AUTOSAR XML (schema 4-2-2)
package /STELLANTIS/EPT/ASWCs
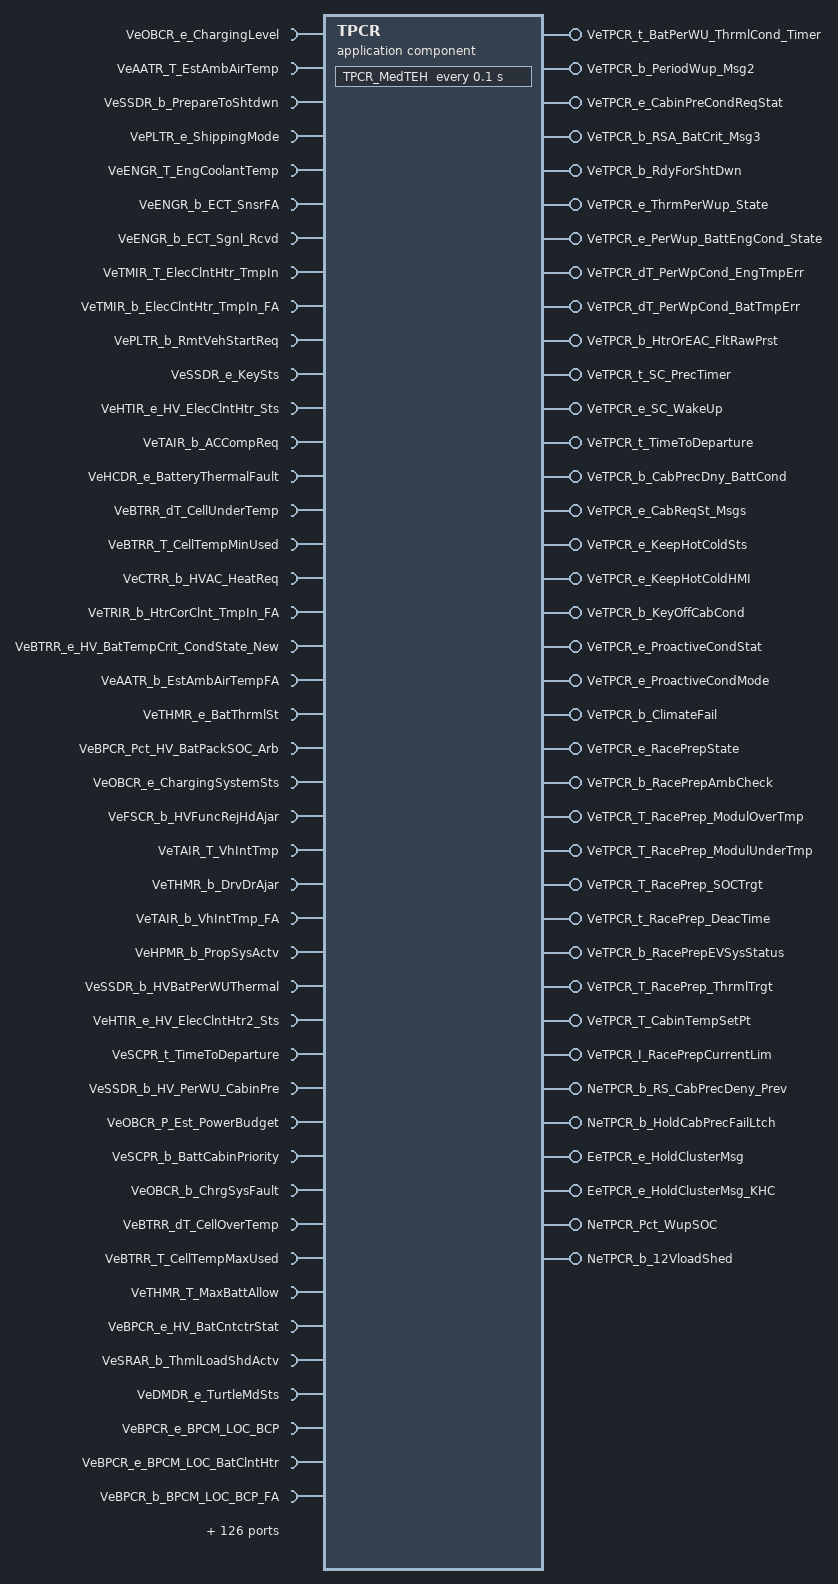
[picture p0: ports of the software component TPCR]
  application sw component type TPCR
    162 x require port:
      VeOBCR_e_ChargingLevel: variation-point={short-label=vpVeOBCR_e_ChargingLevel, sw-syscond=1}, nonqueued-receiver-com-spec{data-element=Value, init-value=CeOBCR_e_ChargingLvlDefault}, required-interface=VeOBCR_e_ChargingLevel
      VeAATR_T_EstAmbAirTemp: variation-point={short-label=vpVeAATR_T_EstAmbAirTemp, sw-syscond=1}, nonqueued-receiver-com-spec{data-element=Value, init-value=0}, required-interface=VeAATR_T_EstAmbAirTemp
      VeSSDR_b_PrepareToShtdwn: variation-point={short-label=vpVeSSDR_b_PrepareToShtdwn, sw-syscond=1}, nonqueued-receiver-com-spec{data-element=Value, init-value=0}, required-interface=VeSSDR_b_PrepareToShtdwn
      VePLTR_e_ShippingMode: variation-point={short-label=vpVePLTR_e_ShippingMode, sw-syscond=1}, nonqueued-receiver-com-spec{data-element=Value, init-value=CePLTR_e_ShipingMode_CUST_MD}, required-interface=VePLTR_e_ShippingMode
      VeENGR_T_EngCoolantTemp: variation-point={short-label=vpVeENGR_T_EngCoolantTemp, sw-syscond=1}, nonqueued-receiver-com-spec{data-element=Value, init-value=0}, required-interface=VeENGR_T_EngCoolantTemp
      VeENGR_b_ECT_SnsrFA: variation-point={short-label=vpVeENGR_b_ECT_SnsrFA, sw-syscond=1}, nonqueued-receiver-com-spec{data-element=Value, init-value=0}, required-interface=VeENGR_b_ECT_SnsrFA
      VeENGR_b_ECT_Sgnl_Rcvd: variation-point={short-label=vpVeENGR_b_ECT_Sgnl_Rcvd, sw-syscond=1}, nonqueued-receiver-com-spec{data-element=Value, init-value=0}, required-interface=VeENGR_b_ECT_Sgnl_Rcvd
      VeTMIR_T_ElecClntHtr_TmpIn: variation-point={short-label=vpVeTMIR_T_ElecClntHtr_TmpIn, sw-syscond=1}, nonqueued-receiver-com-spec{data-element=Value, init-value=0}, required-interface=VeTMIR_T_ElecClntHtr_TmpIn
      VeTMIR_b_ElecClntHtr_TmpIn_FA: variation-point={short-label=vpVeTMIR_b_ElecClntHtr_TmpIn_FA, sw-syscond=1}, nonqueued-receiver-com-spec{data-element=Value, init-value=0}, required-interface=VeTMIR_b_ElecClntHtr_TmpIn_FA
      VePLTR_b_RmtVehStartReq: variation-point={short-label=vpVePLTR_b_RmtVehStartReq, sw-syscond=1}, nonqueued-receiver-com-spec{data-element=Value, init-value=0}, required-interface=VePLTR_b_RmtVehStartReq
      VeSSDR_e_KeySts: variation-point={short-label=vpVeSSDR_e_KeySts, sw-syscond=1}, nonqueued-receiver-com-spec{data-element=Value, init-value=CeSSDR_e_KeyOff}, required-interface=VeSSDR_e_KeySts
      VeHTIR_e_HV_ElecClntHtr_Sts: variation-point={short-label=vpVeHTIR_e_HV_ElecClntHtr_Sts, sw-syscond=1}, nonqueued-receiver-com-spec{data-element=Value, init-value=CeHTIR_e_HtrSts_Off}, required-interface=VeHTIR_e_HV_ElecClntHtr_Sts
      VeTAIR_b_ACCompReq: variation-point={short-label=vpVeTAIR_b_ACCompReq, sw-syscond=1}, nonqueued-receiver-com-spec{data-element=Value, init-value=0}, required-interface=VeTAIR_b_ACCompReq
      VeHCDR_e_BatteryThermalFault: variation-point={short-label=vpVeHCDR_e_BatteryThermalFault, sw-syscond=1}, nonqueued-receiver-com-spec{data-element=Value, init-value=CeHCDR_e_BattThermalNoFault}, required-interface=VeHCDR_e_BatteryThermalFault
      VeBTRR_dT_CellUnderTemp: variation-point={short-label=vpVeBTRR_dT_CellUnderTemp, sw-syscond=1}, nonqueued-receiver-com-spec{data-element=Value, init-value=0}, required-interface=VeBTRR_dT_CellUnderTemp
      VeBTRR_T_CellTempMinUsed: variation-point={short-label=vpVeBTRR_T_CellTempMinUsed, sw-syscond=1}, nonqueued-receiver-com-spec{data-element=Value, init-value=0}, required-interface=VeBTRR_T_CellTempMinUsed
      VeCTRR_b_HVAC_HeatReq: variation-point={short-label=vpVeCTRR_b_HVAC_HeatReq, sw-syscond=1}, nonqueued-receiver-com-spec{data-element=Value, init-value=0}, required-interface=VeCTRR_b_HVAC_HeatReq
      VeTRIR_b_HtrCorClnt_TmpIn_FA: variation-point={short-label=vpVeTRIR_b_HtrCorClnt_TmpIn_FA, sw-syscond=1}, nonqueued-receiver-com-spec{data-element=Value, init-value=0}, required-interface=VeTRIR_b_HtrCorClnt_TmpIn_FA
      VeBTRR_e_HV_BatTempCrit_CondState_New: variation-point={short-label=vpVeBTRR_e_HV_BatTempCrit_CondState_New, sw-syscond=1}, nonqueued-receiver-com-spec{data-element=Value, init-value=CeBTRR_e_BatNotCrit}, required-interface=VeBTRR_e_HV_BatTempCrit_CondState_New
      VeAATR_b_EstAmbAirTempFA: variation-point={short-label=vpVeAATR_b_EstAmbAirTempFA, sw-syscond=1}, nonqueued-receiver-com-spec{data-element=Value, init-value=0}, required-interface=VeAATR_b_EstAmbAirTempFA
      VeTHMR_e_BatThrmlSt: variation-point={short-label=vpVeTHMR_e_BatThrmlSt, sw-syscond=1}, nonqueued-receiver-com-spec{data-element=Value, init-value=CeTHMR_e_NoConditioning}, required-interface=VeTHMR_e_BatThrmlSt
      VeBPCR_Pct_HV_BatPackSOC_Arb: variation-point={short-label=vpVeBPCR_Pct_HV_BatPackSOC_Arb, sw-syscond=1}, nonqueued-receiver-com-spec{data-element=Value, init-value=0}, required-interface=VeBPCR_Pct_HV_BatPackSOC_Arb
      VeOBCR_e_ChargingSystemSts: variation-point={short-label=vpVeOBCR_e_ChargingSystemSts, sw-syscond=1}, nonqueued-receiver-com-spec{data-element=Value, init-value=CeOBCR_e_NotCharging}, required-interface=VeOBCR_e_ChargingSystemSts
      VeFSCR_b_HVFuncRejHdAjar: variation-point={short-label=vpVeFSCR_b_HVFuncRejHdAjar, sw-syscond=1}, nonqueued-receiver-com-spec{data-element=Value, init-value=0}, required-interface=VeFSCR_b_HVFuncRejHdAjar
      VeTAIR_T_VhIntTmp: variation-point={short-label=vpVeTAIR_T_VhIntTmp, sw-syscond=1}, nonqueued-receiver-com-spec{data-element=Value, init-value=0}, required-interface=VeTAIR_T_VhIntTmp
      VeTHMR_b_DrvDrAjar: variation-point={short-label=vpVeTHMR_b_DrvDrAjar, sw-syscond=1}, nonqueued-receiver-com-spec{data-element=Value, init-value=0}, required-interface=VeTHMR_b_DrvDrAjar
      VeTAIR_b_VhIntTmp_FA: variation-point={short-label=vpVeTAIR_b_VhIntTmp_FA, sw-syscond=1}, nonqueued-receiver-com-spec{data-element=Value, init-value=0}, required-interface=VeTAIR_b_VhIntTmp_FA
      VeHPMR_b_PropSysActv: variation-point={short-label=vpVeHPMR_b_PropSysActv, sw-syscond=1}, nonqueued-receiver-com-spec{data-element=Value, init-value=0}, required-interface=VeHPMR_b_PropSysActv
      VeSSDR_b_HVBatPerWUThermal: variation-point={short-label=vpVeSSDR_b_HVBatPerWUThermal, sw-syscond=1}, nonqueued-receiver-com-spec{data-element=Value, init-value=0}, required-interface=VeSSDR_b_HVBatPerWUThermal
      VeHTIR_e_HV_ElecClntHtr2_Sts: variation-point={short-label=vpVeHTIR_e_HV_ElecClntHtr2_Sts, sw-syscond=1}, nonqueued-receiver-com-spec{data-element=Value, init-value=CeHTIR_e_HtrSts_Off}, required-interface=VeHTIR_e_HV_ElecClntHtr2_Sts
      VeSCPR_t_TimeToDeparture: variation-point={short-label=vpVeSCPR_t_TimeToDeparture, sw-syscond=1}, nonqueued-receiver-com-spec{data-element=Value, init-value=0}, required-interface=VeSCPR_t_TimeToDeparture
      VeSSDR_b_HV_PerWU_CabinPre: variation-point={short-label=vpVeSSDR_b_HV_PerWU_CabinPre, sw-syscond=1}, nonqueued-receiver-com-spec{data-element=Value, init-value=0}, required-interface=VeSSDR_b_HV_PerWU_CabinPre
      VeOBCR_P_Est_PowerBudget: variation-point={short-label=vpVeOBCR_P_Est_PowerBudget, sw-syscond=1}, nonqueued-receiver-com-spec{data-element=Value, init-value=0}, required-interface=VeOBCR_P_Est_PowerBudget
      VeSCPR_b_BattCabinPriority: variation-point={short-label=vpVeSCPR_b_BattCabinPriority, sw-syscond=1}, nonqueued-receiver-com-spec{data-element=Value, init-value=0}, required-interface=VeSCPR_b_BattCabinPriority
      VeOBCR_b_ChrgSysFault: variation-point={short-label=vpVeOBCR_b_ChrgSysFault, sw-syscond=1}, nonqueued-receiver-com-spec{data-element=Value, init-value=0}, required-interface=VeOBCR_b_ChrgSysFault
      VeBTRR_dT_CellOverTemp: variation-point={short-label=vpVeBTRR_dT_CellOverTemp, sw-syscond=1}, nonqueued-receiver-com-spec{data-element=Value, init-value=0}, required-interface=VeBTRR_dT_CellOverTemp
      VeBTRR_T_CellTempMaxUsed: variation-point={short-label=vpVeBTRR_T_CellTempMaxUsed, sw-syscond=1}, nonqueued-receiver-com-spec{data-element=Value, init-value=0}, required-interface=VeBTRR_T_CellTempMaxUsed
      VeTHMR_T_MaxBattAllow: variation-point={short-label=vpVeTHMR_T_MaxBattAllow, sw-syscond=1}, nonqueued-receiver-com-spec{data-element=Value, init-value=0}, required-interface=VeTHMR_T_MaxBattAllow
      VeBPCR_e_HV_BatCntctrStat: variation-point={short-label=vpVeBPCR_e_HV_BatCntctrStat, sw-syscond=1}, nonqueued-receiver-com-spec{data-element=Value, init-value=CeHVTR_e_Open}, required-interface=VeBPCR_e_HV_BatCntctrStat
      VeSRAR_b_ThmlLoadShdActv: variation-point={short-label=vpVeSRAR_b_ThmlLoadShdActv, sw-syscond=1}, nonqueued-receiver-com-spec{data-element=Value, init-value=0}, required-interface=VeSRAR_b_ThmlLoadShdActv
      VeDMDR_e_TurtleMdSts: variation-point={short-label=vpVeDMDR_e_TurtleMdSts, sw-syscond=1}, nonqueued-receiver-com-spec{data-element=Value, init-value=CeDMDR_e_No_Turtle_Mode}, required-interface=VeDMDR_e_TurtleMdSts
      VeBPCR_e_BPCM_LOC_BCP: variation-point={short-label=vpVeBPCR_e_BPCM_LOC_BCP, sw-syscond=1}, nonqueued-receiver-com-spec{data-element=Value, init-value=CeBPCR_e_LOC_BCP_False}, required-interface=VeBPCR_e_BPCM_LOC_BCP
      VeBPCR_e_BPCM_LOC_BatClntHtr: variation-point={short-label=vpVeBPCR_e_BPCM_LOC_BatClntHtr, sw-syscond=1}, nonqueued-receiver-com-spec{data-element=Value, init-value=CeBPCR_e_LOC_BatClntHtr_False}, required-interface=VeBPCR_e_BPCM_LOC_BatClntHtr
      VeBPCR_b_BPCM_LOC_BCP_FA: variation-point={short-label=vpVeBPCR_b_BPCM_LOC_BCP_FA, sw-syscond=1}, nonqueued-receiver-com-spec{data-element=Value, init-value=0}, required-interface=VeBPCR_b_BPCM_LOC_BCP_FA
      VeBPCR_b_BPCM_LOC_BatClntHtr_FA: variation-point={short-label=vpVeBPCR_b_BPCM_LOC_BatClntHtr_FA, sw-syscond=1}, nonqueued-receiver-com-spec{data-element=Value, init-value=0}, required-interface=VeBPCR_b_BPCM_LOC_BatClntHtr_FA
      VePMIR_e_LTActvPumpDryRun: variation-point={short-label=vpVePMIR_e_LTActvPumpDryRun, sw-syscond=1}, nonqueued-receiver-com-spec{data-element=Value, init-value=CePMPR_e_FTSNA_False}, required-interface=VePMIR_e_LTActvPumpDryRun
      VePMIR_b_LTActvPumpDryRun_FA: variation-point={short-label=vpVePMIR_b_LTActvPumpDryRun_FA, sw-syscond=1}, nonqueued-receiver-com-spec{data-element=Value, init-value=0}, required-interface=VePMIR_b_LTActvPumpDryRun_FA
      VePMTR_b_ThrmlSystRly_EnblCmnd: variation-point={short-label=vpVePMTR_b_ThrmlSystRly_EnblCmnd, sw-syscond=1}, nonqueued-receiver-com-spec{data-element=Value, init-value=0}, required-interface=VePMTR_b_ThrmlSystRly_EnblCmnd
      VeFSCR_b_RadFan_FltDtct: variation-point={short-label=vpVeFSCR_b_RadFan_FltDtct, sw-syscond=1}, nonqueued-receiver-com-spec{data-element=Value, init-value=0}, required-interface=VeFSCR_b_RadFan_FltDtct
      VePMIR_e_HTAuxPumpDryRun: variation-point={short-label=vpVePMIR_e_HTAuxPumpDryRun, sw-syscond=1}, nonqueued-receiver-com-spec{data-element=Value, init-value=CePMPR_e_FTSNA_False}, required-interface=VePMIR_e_HTAuxPumpDryRun
      VePMIR_b_HTAuxPumpDryRun_FA: variation-point={short-label=vpVePMIR_b_HTAuxPumpDryRun_FA, sw-syscond=1}, nonqueued-receiver-com-spec{data-element=Value, init-value=0}, required-interface=VePMIR_b_HTAuxPumpDryRun_FA
      VeHTIR_e_HV_ElecClntHtr3_Sts: variation-point={short-label=vpVeHTIR_e_HV_ElecClntHtr3_Sts, sw-syscond=1}, nonqueued-receiver-com-spec{data-element=Value, init-value=CeHTIR_e_HtrSts_Off}, required-interface=VeHTIR_e_HV_ElecClntHtr3_Sts
      VeHTIR_e_HV_ElecClntHtr4_Sts: variation-point={short-label=vpVeHTIR_e_HV_ElecClntHtr4_Sts, sw-syscond=1}, nonqueued-receiver-com-spec{data-element=Value, init-value=CeHTIR_e_HtrSts_Off}, required-interface=VeHTIR_e_HV_ElecClntHtr4_Sts
      VeOBCR_P_AvalPwrForThmr: variation-point={short-label=vpVeOBCR_P_AvalPwrForThmr, sw-syscond=1}, nonqueued-receiver-com-spec{data-element=Value, init-value=0}, required-interface=VeOBCR_P_AvalPwrForThmr
      VeTRIR_e_HVACSt: variation-point={short-label=vpVeTRIR_e_HVACSt, sw-syscond=1}, nonqueued-receiver-com-spec{data-element=Value, init-value=CeTRIR_e_HVAC_Off}, required-interface=VeTRIR_e_HVACSt
      VeTRIR_b_SCCActv: variation-point={short-label=vpVeTRIR_b_SCCActv, sw-syscond=1}, nonqueued-receiver-com-spec{data-element=Value, init-value=0}, required-interface=VeTRIR_b_SCCActv
      VeHCDR_b_HVC_Heater_FltDtct: variation-point={short-label=vpVeHCDR_b_HVC_Heater_FltDtct, sw-syscond=1}, nonqueued-receiver-com-spec{data-element=Value, init-value=0}, required-interface=VeHCDR_b_HVC_Heater_FltDtct
      VeHCDR_b_HV_Heater2_FltDtct: variation-point={short-label=vpVeHCDR_b_HV_Heater2_FltDtct, sw-syscond=1}, nonqueued-receiver-com-spec{data-element=Value, init-value=0}, required-interface=VeHCDR_b_HV_Heater2_FltDtct
      VeSCPR_T_CabinTempSetPt: variation-point={short-label=vpVeSCPR_T_CabinTempSetPt, sw-syscond=1}, nonqueued-receiver-com-spec{data-element=Value, init-value=0}, required-interface=VeSCPR_T_CabinTempSetPt
      VeSCPR_e_SchCP_Allow: variation-point={short-label=vpVeSCPR_e_SchCP_Allow, sw-syscond=1}, nonqueued-receiver-com-spec{data-element=Value, init-value=CeCITR_e_AnyTime}, required-interface=VeSCPR_e_SchCP_Allow
      VeSSDR_b_HVBatPerWU12VChrg: variation-point={short-label=vpVeSSDR_b_HVBatPerWU12VChrg, sw-syscond=1}, nonqueued-receiver-com-spec{data-element=Value, init-value=0}, required-interface=VeSSDR_b_HVBatPerWU12VChrg
      VeTRIR_b_Comfort_EnblAct: variation-point={short-label=vpVeTRIR_b_Comfort_EnblAct, sw-syscond=1}, nonqueued-receiver-com-spec{data-element=Value, init-value=0}, required-interface=VeTRIR_b_Comfort_EnblAct
      VeTRIR_b_KeepHotColdButtonStatus: variation-point={short-label=vpVeTRIR_b_KeepHotColdButtonStatus, sw-syscond=1}, nonqueued-receiver-com-spec{data-element=Value, init-value=0}, required-interface=VeTRIR_b_KeepHotColdButtonStatus
      VeTRIR_b_TrunkStatus: variation-point={short-label=vpVeTRIR_b_TrunkStatus, sw-syscond=1}, nonqueued-receiver-com-spec{data-element=Value, init-value=0}, required-interface=VeTRIR_b_TrunkStatus
      VeTRIR_b_LoadShed: variation-point={short-label=vpVeTRIR_b_LoadShed, sw-syscond=1}, nonqueued-receiver-com-spec{data-element=Value, init-value=0}, required-interface=VeTRIR_b_LoadShed
      VeCITR_P_ChargingDestinationPwr: variation-point={short-label=vpVeCITR_P_ChargingDestinationPwr, sw-syscond=1}, nonqueued-receiver-com-spec{data-element=Value, init-value=0}, required-interface=VeCITR_P_ChargingDestinationPwr
      VeCITR_t_TimeToCharge: variation-point={short-label=vpVeCITR_t_TimeToCharge, sw-syscond=1}, nonqueued-receiver-com-spec{data-element=Value, init-value=0}, required-interface=VeCITR_t_TimeToCharge
      VeCITR_l_DistanceToCharge: variation-point={short-label=vpVeCITR_l_DistanceToCharge, sw-syscond=1}, nonqueued-receiver-com-spec{data-element=Value, init-value=0}, required-interface=VeCITR_l_DistanceToCharge
      VeERER_l_EstRange: variation-point={short-label=vpVeERER_l_EstRange, sw-syscond=1}, nonqueued-receiver-com-spec{data-element=Value, init-value=0}, required-interface=VeERER_l_EstRange
      VeTHMR_b_BattAllowed: variation-point={short-label=vpVeTHMR_b_BattAllowed, sw-syscond=1}, nonqueued-receiver-com-spec{data-element=Value, init-value=0}, required-interface=VeTHMR_b_BattAllowed
      VeTHMR_T_PPCTIS_Arb: variation-point={short-label=vpVeTHMR_T_PPCTIS_Arb, sw-syscond=1}, nonqueued-receiver-com-spec{data-element=Value, init-value=0}, required-interface=VeTHMR_T_PPCTIS_Arb
      VeCITR_b_ChargingDestinationPwr_FA: variation-point={short-label=vpVeCITR_b_ChargingDestinationPwr_FA, sw-syscond=1}, nonqueued-receiver-com-spec{data-element=Value, init-value=0}, required-interface=VeCITR_b_ChargingDestinationPwr_FA
      VeCITR_b_TimeToCharge_FA: variation-point={short-label=vpVeCITR_b_TimeToCharge_FA, sw-syscond=1}, nonqueued-receiver-com-spec{data-element=Value, init-value=0}, required-interface=VeCITR_b_TimeToCharge_FA
      VeCITR_b_DistanceToCharge_FA: variation-point={short-label=vpVeCITR_b_DistanceToCharge_FA, sw-syscond=1}, nonqueued-receiver-com-spec{data-element=Value, init-value=0}, required-interface=VeCITR_b_DistanceToCharge_FA
      VeENGR_b_EngSysLowFuel: variation-point={short-label=vpVeENGR_b_EngSysLowFuel, sw-syscond=1}, nonqueued-receiver-com-spec{data-element=Value, init-value=0}, required-interface=VeENGR_b_EngSysLowFuel
      VePLTR_b_HotEnablerReq: variation-point={short-label=vpVePLTR_b_HotEnablerReq, sw-syscond=1}, nonqueued-receiver-com-spec{data-element=Value, init-value=0}, required-interface=VePLTR_b_HotEnablerReq
      VeCITR_e_FOTA_Install_Type: variation-point={short-label=vpVeCITR_e_FOTA_Install_Type, sw-syscond=1}, nonqueued-receiver-com-spec{data-element=Value, init-value=CeCITR_e_NoFOTA}, required-interface=VeCITR_e_FOTA_Install_Type
      VeVTLR_e_DschrgSysSts: variation-point={short-label=vpVeVTLR_e_DschrgSysSts, sw-syscond=1}, nonqueued-receiver-com-spec{data-element=Value, init-value=CeVTLR_e_DschrgInactv}, required-interface=VeVTLR_e_DschrgSysSts
      VeDMAB_y_StatusByte_HiSpdCANCommBus: variation-point={short-label=vpVeDMAB_y_StatusByte_HiSpdCANCommBus, sw-syscond=1}, nonqueued-receiver-com-spec{data-element=Value, init-value=0}, required-interface=VeDMAB_y_StatusByte_HiSpdCANCommBus
      VeDMAB_y_StatusByte_LostCommBCM: variation-point={short-label=vpVeDMAB_y_StatusByte_LostCommBCM, sw-syscond=1}, nonqueued-receiver-com-spec{data-element=Value, init-value=0}, required-interface=VeDMAB_y_StatusByte_LostCommBCM
      VeDMAB_y_StatusByte_CT2_SnsrCktHi: variation-point={short-label=vpVeDMAB_y_StatusByte_CT2_SnsrCktHi, sw-syscond=1}, nonqueued-receiver-com-spec{data-element=Value, init-value=0}, required-interface=VeDMAB_y_StatusByte_CT2_SnsrCktHi
      VeDMAB_y_StatusByte_CT2_SnsrCktLo: variation-point={short-label=vpVeDMAB_y_StatusByte_CT2_SnsrCktLo, sw-syscond=1}, nonqueued-receiver-com-spec{data-element=Value, init-value=0}, required-interface=VeDMAB_y_StatusByte_CT2_SnsrCktLo
      VeDMAB_y_StatusByte_CT2_SnsrPerf: variation-point={short-label=vpVeDMAB_y_StatusByte_CT2_SnsrPerf, sw-syscond=1}, nonqueued-receiver-com-spec{data-element=Value, init-value=0}, required-interface=VeDMAB_y_StatusByte_CT2_SnsrPerf
      VeDMAB_y_StatusByte_CoolPmpATempSnsrPerf: variation-point={short-label=vpVeDMAB_y_StatusByte_CoolPmpATempSnsrPerf, sw-syscond=1}, nonqueued-receiver-com-spec{data-element=Value, init-value=0}, required-interface=VeDMAB_y_StatusByte_CoolPmpATempSnsrPerf
      VeDMAB_y_StatusByte_CoolantVlvB_CktHi: variation-point={short-label=vpVeDMAB_y_StatusByte_CoolantVlvB_CktHi, sw-syscond=1}, nonqueued-receiver-com-spec{data-element=Value, init-value=0}, required-interface=VeDMAB_y_StatusByte_CoolantVlvB_CktHi
      VeDMAB_y_StatusByte_CoolantVlvB_CktLo: variation-point={short-label=vpVeDMAB_y_StatusByte_CoolantVlvB_CktLo, sw-syscond=1}, nonqueued-receiver-com-spec{data-element=Value, init-value=0}, required-interface=VeDMAB_y_StatusByte_CoolantVlvB_CktLo
      VeDMAB_y_StatusByte_CoolantVlvB_Ckt: variation-point={short-label=vpVeDMAB_y_StatusByte_CoolantVlvB_Ckt, sw-syscond=1}, nonqueued-receiver-com-spec{data-element=Value, init-value=0}, required-interface=VeDMAB_y_StatusByte_CoolantVlvB_Ckt
      VeDMAB_y_StatusByte_CoolantVlvB_StkClsd: variation-point={short-label=vpVeDMAB_y_StatusByte_CoolantVlvB_StkClsd, sw-syscond=1}, nonqueued-receiver-com-spec{data-element=Value, init-value=0}, required-interface=VeDMAB_y_StatusByte_CoolantVlvB_StkClsd
      VeDMAB_y_StatusByte_ECH_TempIn: variation-point={short-label=vpVeDMAB_y_StatusByte_ECH_TempIn, sw-syscond=1}, nonqueued-receiver-com-spec{data-element=Value, init-value=0}, required-interface=VeDMAB_y_StatusByte_ECH_TempIn
      VeDMAB_y_StatusByte_ECH_TempOut: variation-point={short-label=vpVeDMAB_y_StatusByte_ECH_TempOut, sw-syscond=1}, nonqueued-receiver-com-spec{data-element=Value, init-value=0}, required-interface=VeDMAB_y_StatusByte_ECH_TempOut
      VeDMAB_y_StatusByte_LostCommCoolHtrA: variation-point={short-label=vpVeDMAB_y_StatusByte_LostCommCoolHtrA, sw-syscond=1}, nonqueued-receiver-com-spec{data-element=Value, init-value=0}, required-interface=VeDMAB_y_StatusByte_LostCommCoolHtrA
      VeDMAB_y_StatusByte_LostCommHighVolCabinAirHtr: variation-point={short-label=vpVeDMAB_y_StatusByte_LostCommHighVolCabinAirHtr, sw-syscond=1}, nonqueued-receiver-com-spec{data-element=Value, init-value=0}, required-interface=VeDMAB_y_StatusByte_LostCommHighVolCabinAirHtr
      VeDMAB_y_StatusByte_CoolPmpACtrlCktPerf: variation-point={short-label=vpVeDMAB_y_StatusByte_CoolPmpACtrlCktPerf, sw-syscond=1}, nonqueued-receiver-com-spec{data-element=Value, init-value=0}, required-interface=VeDMAB_y_StatusByte_CoolPmpACtrlCktPerf
      VeDMAB_y_StatusByte_LIN2_BusOff: variation-point={short-label=vpVeDMAB_y_StatusByte_LIN2_BusOff, sw-syscond=1}, nonqueued-receiver-com-spec{data-element=Value, init-value=0}, required-interface=VeDMAB_y_StatusByte_LIN2_BusOff
      VeDMAB_y_StatusByte_LostCommCoolPmpA: variation-point={short-label=vpVeDMAB_y_StatusByte_LostCommCoolPmpA, sw-syscond=1}, nonqueued-receiver-com-spec{data-element=Value, init-value=0}, required-interface=VeDMAB_y_StatusByte_LostCommCoolPmpA
      VeDMAB_y_StatusByte_CoolHeaterAPerf: variation-point={short-label=vpVeDMAB_y_StatusByte_CoolHeaterAPerf, sw-syscond=1}, nonqueued-receiver-com-spec{data-element=Value, init-value=0}, required-interface=VeDMAB_y_StatusByte_CoolHeaterAPerf
      VeDMAB_y_StatusByte_HighVolCabinAirHtrperf: variation-point={short-label=vpVeDMAB_y_StatusByte_HighVolCabinAirHtrperf, sw-syscond=1}, nonqueued-receiver-com-spec{data-element=Value, init-value=0}, required-interface=VeDMAB_y_StatusByte_HighVolCabinAirHtrperf
      VeDMAB_y_StatusByte_EACPerf: variation-point={short-label=vpVeDMAB_y_StatusByte_EACPerf, sw-syscond=1}, nonqueued-receiver-com-spec{data-element=Value, init-value=0}, required-interface=VeDMAB_y_StatusByte_EACPerf
      VeDMAB_y_StatusByte_LostCommEAC: variation-point={short-label=vpVeDMAB_y_StatusByte_LostCommEAC, sw-syscond=1}, nonqueued-receiver-com-spec{data-element=Value, init-value=0}, required-interface=VeDMAB_y_StatusByte_LostCommEAC
      VeDMAB_y_StatusByte_EvapRefriShutoffCtrlCktFlt: variation-point={short-label=vpVeDMAB_y_StatusByte_EvapRefriShutoffCtrlCktFlt, sw-syscond=1}, nonqueued-receiver-com-spec{data-element=Value, init-value=0}, required-interface=VeDMAB_y_StatusByte_EvapRefriShutoffCtrlCktFlt
      VeDMAB_y_StatusByte_EvapRefriShutoffCtrlshrtBattFlt: variation-point={short-label=vpVeDMAB_y_StatusByte_EvapRefriShutoffCtrlshrtBattFlt, sw-syscond=1}, nonqueued-receiver-com-spec{data-element=Value, init-value=0}, required-interface=VeDMAB_y_StatusByte_EvapRefriShutoffCtrlshrtBattFlt
      VeDMAB_y_StatusByte_EvapRefrishutoffCtrlShrtGndFlt: variation-point={short-label=vpVeDMAB_y_StatusByte_EvapRefrishutoffCtrlShrtGndFlt, sw-syscond=1}, nonqueued-receiver-com-spec{data-element=Value, init-value=0}, required-interface=VeDMAB_y_StatusByte_EvapRefrishutoffCtrlShrtGndFlt
      VeDMAB_y_StatusByte_AC_RefrigPresSnsrAHi: variation-point={short-label=vpVeDMAB_y_StatusByte_AC_RefrigPresSnsrAHi, sw-syscond=1}, nonqueued-receiver-com-spec{data-element=Value, init-value=0}, required-interface=VeDMAB_y_StatusByte_AC_RefrigPresSnsrAHi
      VeDMAB_y_StatusByte_AC_RefrigPresSnsrALo: variation-point={short-label=vpVeDMAB_y_StatusByte_AC_RefrigPresSnsrALo, sw-syscond=1}, nonqueued-receiver-com-spec{data-element=Value, init-value=0}, required-interface=VeDMAB_y_StatusByte_AC_RefrigPresSnsrALo
      VeDMAB_y_StatusByte_AC_RefrigPresSnsrAPerf: variation-point={short-label=vpVeDMAB_y_StatusByte_AC_RefrigPresSnsrAPerf, sw-syscond=1}, nonqueued-receiver-com-spec{data-element=Value, init-value=0}, required-interface=VeDMAB_y_StatusByte_AC_RefrigPresSnsrAPerf
      VeDMAB_y_StatusByte_CommBusOff: variation-point={short-label=vpVeDMAB_y_StatusByte_CommBusOff, sw-syscond=1}, nonqueued-receiver-com-spec{data-element=Value, init-value=0}, required-interface=VeDMAB_y_StatusByte_CommBusOff
      VeDMAB_y_StatusByte_CommBus_B_Off: variation-point={short-label=vpVeDMAB_y_StatusByte_CommBus_B_Off, sw-syscond=1}, nonqueued-receiver-com-spec{data-element=Value, init-value=0}, required-interface=VeDMAB_y_StatusByte_CommBus_B_Off
      VeDMAB_y_StatusByte_BattCoolPmpHtrBTempSnsrPerf: variation-point={short-label=vpVeDMAB_y_StatusByte_BattCoolPmpHtrBTempSnsrPerf, sw-syscond=1}, nonqueued-receiver-com-spec{data-element=Value, init-value=0}, required-interface=VeDMAB_y_StatusByte_BattCoolPmpHtrBTempSnsrPerf
      VeDMAB_y_StatusByte_BattHeat: variation-point={short-label=vpVeDMAB_y_StatusByte_BattHeat, sw-syscond=1}, nonqueued-receiver-com-spec{data-element=Value, init-value=0}, required-interface=VeDMAB_y_StatusByte_BattHeat
      VeDMAB_y_StatusByte_CoolantHeaterBPerf: variation-point={short-label=vpVeDMAB_y_StatusByte_CoolantHeaterBPerf, sw-syscond=1}, nonqueued-receiver-com-spec{data-element=Value, init-value=0}, required-interface=VeDMAB_y_StatusByte_CoolantHeaterBPerf
      VeDMAB_y_StatusByte_HeatingElmntPerf: variation-point={short-label=vpVeDMAB_y_StatusByte_HeatingElmntPerf, sw-syscond=1}, nonqueued-receiver-com-spec{data-element=Value, init-value=0}, required-interface=VeDMAB_y_StatusByte_HeatingElmntPerf
      VeDMAB_y_StatusByte_LosCommBECM_A_CANC11: variation-point={short-label=vpVeDMAB_y_StatusByte_LosCommBECM_A_CANC11, sw-syscond=1}, nonqueued-receiver-com-spec{data-element=Value, init-value=0}, required-interface=VeDMAB_y_StatusByte_LosCommBECM_A_CANC11
      VeDMAB_y_StatusByte_LosCommBECM_A: variation-point={short-label=vpVeDMAB_y_StatusByte_LosCommBECM_A, sw-syscond=1}, nonqueued-receiver-com-spec{data-element=Value, init-value=0}, required-interface=VeDMAB_y_StatusByte_LosCommBECM_A
      VeDMAB_y_StatusByte_CoolantVlvA_CktHi: variation-point={short-label=vpVeDMAB_y_StatusByte_CoolantVlvA_CktHi, sw-syscond=1}, nonqueued-receiver-com-spec{data-element=Value, init-value=0}, required-interface=VeDMAB_y_StatusByte_CoolantVlvA_CktHi
      VeDMAB_y_StatusByte_CoolantVlvA_CktLo: variation-point={short-label=vpVeDMAB_y_StatusByte_CoolantVlvA_CktLo, sw-syscond=1}, nonqueued-receiver-com-spec{data-element=Value, init-value=0}, required-interface=VeDMAB_y_StatusByte_CoolantVlvA_CktLo
      VeDMAB_y_StatusByte_CoolantVlvA_Ckt: variation-point={short-label=vpVeDMAB_y_StatusByte_CoolantVlvA_Ckt, sw-syscond=1}, nonqueued-receiver-com-spec{data-element=Value, init-value=0}, required-interface=VeDMAB_y_StatusByte_CoolantVlvA_Ckt
      VeDMAB_y_StatusByte_CoolantVlvA_Perf: variation-point={short-label=vpVeDMAB_y_StatusByte_CoolantVlvA_Perf, sw-syscond=1}, nonqueued-receiver-com-spec{data-element=Value, init-value=0}, required-interface=VeDMAB_y_StatusByte_CoolantVlvA_Perf
      VeDMAB_y_StatusByte_BattCoolPmpATempSnsrPerf: variation-point={short-label=vpVeDMAB_y_StatusByte_BattCoolPmpATempSnsrPerf, sw-syscond=1}, nonqueued-receiver-com-spec{data-element=Value, init-value=0}, required-interface=VeDMAB_y_StatusByte_BattCoolPmpATempSnsrPerf
      VeDMAB_y_StatusByte_BattCoolPmpPerf: variation-point={short-label=vpVeDMAB_y_StatusByte_BattCoolPmpPerf, sw-syscond=1}, nonqueued-receiver-com-spec{data-element=Value, init-value=0}, required-interface=VeDMAB_y_StatusByte_BattCoolPmpPerf
      VeDMAB_y_StatusByte_BattCoolLvlLow: variation-point={short-label=vpVeDMAB_y_StatusByte_BattCoolLvlLow, sw-syscond=1}, nonqueued-receiver-com-spec{data-element=Value, init-value=0}, required-interface=VeDMAB_y_StatusByte_BattCoolLvlLow
      VeDMAB_y_StatusByte_BattCoolLvlSnsCkt: variation-point={short-label=vpVeDMAB_y_StatusByte_BattCoolLvlSnsCkt, sw-syscond=1}, nonqueued-receiver-com-spec{data-element=Value, init-value=0}, required-interface=VeDMAB_y_StatusByte_BattCoolLvlSnsCkt
      VeDMAB_y_StatusByte_CoolOutTempSnsCkt: variation-point={short-label=vpVeDMAB_y_StatusByte_CoolOutTempSnsCkt, sw-syscond=1}, nonqueued-receiver-com-spec{data-element=Value, init-value=0}, required-interface=VeDMAB_y_StatusByte_CoolOutTempSnsCkt
      VeDMAB_y_StatusByte_HB_CT_SnsrPerf: variation-point={short-label=vpVeDMAB_y_StatusByte_HB_CT_SnsrPerf, sw-syscond=1}, nonqueued-receiver-com-spec{data-element=Value, init-value=0}, required-interface=VeDMAB_y_StatusByte_HB_CT_SnsrPerf
      VeDMAB_y_StatusByte_ThrmlRlyCtrlCkt: variation-point={short-label=vpVeDMAB_y_StatusByte_ThrmlRlyCtrlCkt, sw-syscond=1}, nonqueued-receiver-com-spec{data-element=Value, init-value=0}, required-interface=VeDMAB_y_StatusByte_ThrmlRlyCtrlCkt
      VeTIMR_e_RacePrep: variation-point={short-label=vpVeTIMR_e_RacePrep, sw-syscond=1}, nonqueued-receiver-com-spec{data-element=Value, init-value=CeTIMR_e_RacePrep_Off}, required-interface=VeTIMR_e_RacePrep
      VeTIMR_e_RacePrepRaceTypeSts: variation-point={short-label=vpVeTIMR_e_RacePrepRaceTypeSts, sw-syscond=1}, nonqueued-receiver-com-spec{data-element=Value, init-value=CeTIMR_e_RaceType_Drag}, required-interface=VeTIMR_e_RacePrepRaceTypeSts
      VeHMIR_e_HEV_LMP_RQ: variation-point={short-label=vpVeHMIR_e_HEV_LMP_RQ, sw-syscond=1}, nonqueued-receiver-com-spec{data-element=Value, init-value=CeHMIR_e_HEV_LMP_OFF}, required-interface=VeHMIR_e_HEV_LMP_RQ
      VeSRAR_b_Disable_RaceStart: variation-point={short-label=vpVeSRAR_b_Disable_RaceStart, sw-syscond=1}, nonqueued-receiver-com-spec{data-element=Value, init-value=0}, required-interface=VeSRAR_b_Disable_RaceStart
      VeCSVR_v_VehSpd: variation-point={short-label=vpVeCSVR_v_VehSpd, sw-syscond=1}, nonqueued-receiver-com-spec{data-element=Value, init-value=0}, required-interface=VeCSVR_v_VehSpd
      VeTHMR_e_CabHeatThermalState: variation-point={short-label=vpVeTHMR_e_CabHeatThermalState, sw-syscond=1}, nonqueued-receiver-com-spec{data-element=Value, init-value=CeTHMR_e_NoCabinHeating}, required-interface=VeTHMR_e_CabHeatThermalState
      VeTHMR_e_CabCoolThermalState: variation-point={short-label=vpVeTHMR_e_CabCoolThermalState, sw-syscond=1}, nonqueued-receiver-com-spec{data-element=Value, init-value=CeTHMR_e_NoCabinCooling}, required-interface=VeTHMR_e_CabCoolThermalState
      VeTAIR_Pct_FrtBlwrCmd: variation-point={short-label=vpVeTAIR_Pct_FrtBlwrCmd, sw-syscond=1}, nonqueued-receiver-com-spec{data-element=Value, init-value=0}, required-interface=VeTAIR_Pct_FrtBlwrCmd
      VeHVTR_I_HV_BattCurrent: variation-point={short-label=vpVeHVTR_I_HV_BattCurrent, sw-syscond=1}, nonqueued-receiver-com-spec{data-element=Value, init-value=0}, required-interface=VeHVTR_I_HV_BattCurrent
      VeBTRR_T_BTISBTIS2_Max: variation-point={short-label=vpVeBTRR_T_BTISBTIS2_Max, sw-syscond=1}, nonqueued-receiver-com-spec{data-element=Value, init-value=0}, required-interface=VeBTRR_T_BTISBTIS2_Max
      VeBTRR_T_CellTempAvgUsed: variation-point={short-label=vpVeBTRR_T_CellTempAvgUsed, sw-syscond=1}, nonqueued-receiver-com-spec{data-element=Value, init-value=0}, required-interface=VeBTRR_T_CellTempAvgUsed
      VeDMAB_y_StatusByte_LIN3_BusOff: variation-point={short-label=vpVeDMAB_y_StatusByte_LIN3_BusOff, sw-syscond=1}, nonqueued-receiver-com-spec{data-element=Value, init-value=0}, required-interface=VeDMAB_y_StatusByte_LIN3_BusOff
      VeDMAB_y_StatusByte_LIN1_BusOff: variation-point={short-label=vpVeDMAB_y_StatusByte_LIN1_BusOff, sw-syscond=1}, nonqueued-receiver-com-spec{data-element=Value, init-value=0}, required-interface=VeDMAB_y_StatusByte_LIN1_BusOff
      VeDMAB_y_StatusByte_LostCommHB_CoolPmp: variation-point={short-label=vpVeDMAB_y_StatusByte_LostCommHB_CoolPmp, sw-syscond=1}, nonqueued-receiver-com-spec{data-element=Value, init-value=0}, required-interface=VeDMAB_y_StatusByte_LostCommHB_CoolPmp
      VeDMAB_y_StatusByte_BattCoolPmpOveSpd: variation-point={short-label=vpVeDMAB_y_StatusByte_BattCoolPmpOveSpd, sw-syscond=1}, nonqueued-receiver-com-spec{data-element=Value, init-value=0}, required-interface=VeDMAB_y_StatusByte_BattCoolPmpOveSpd
      VeDMAB_y_StatusByte_BattCool: variation-point={short-label=vpVeDMAB_y_StatusByte_BattCool, sw-syscond=1}, nonqueued-receiver-com-spec{data-element=Value, init-value=0}, required-interface=VeDMAB_y_StatusByte_BattCool
      VeDMAB_y_StatusByte_CoolantVlvB_StkOpn: variation-point={short-label=vpVeDMAB_y_StatusByte_CoolantVlvB_StkOpn, sw-syscond=1}, nonqueued-receiver-com-spec{data-element=Value, init-value=0}, required-interface=VeDMAB_y_StatusByte_CoolantVlvB_StkOpn
      VeDMAB_y_StatusByte_LostCommACRefrigExpVlvActA: variation-point={short-label=vpVeDMAB_y_StatusByte_LostCommACRefrigExpVlvActA, sw-syscond=1}, nonqueued-receiver-com-spec{data-element=Value, init-value=0}, required-interface=VeDMAB_y_StatusByte_LostCommACRefrigExpVlvActA
      VeVLDR_b_EXV_PerfDiag_FltDtct: variation-point={short-label=vpVeVLDR_b_EXV_PerfDiag_FltDtct, sw-syscond=1}, nonqueued-receiver-com-spec{data-element=Value, init-value=0}, required-interface=VeVLDR_b_EXV_PerfDiag_FltDtct
      VeVLDR_b_EXV_TempElctrFlt_FltDtct: variation-point={short-label=vpVeVLDR_b_EXV_TempElctrFlt_FltDtct, sw-syscond=1}, nonqueued-receiver-com-spec{data-element=Value, init-value=0}, required-interface=VeVLDR_b_EXV_TempElctrFlt_FltDtct
      VeVLDR_b_EXV_TempSens_FltDtct: variation-point={short-label=vpVeVLDR_b_EXV_TempSens_FltDtct, sw-syscond=1}, nonqueued-receiver-com-spec{data-element=Value, init-value=0}, required-interface=VeVLDR_b_EXV_TempSens_FltDtct
      VeVLDR_b_EXV_PressSens_FltDtct: variation-point={short-label=vpVeVLDR_b_EXV_PressSens_FltDtct, sw-syscond=1}, nonqueued-receiver-com-spec{data-element=Value, init-value=0}, required-interface=VeVLDR_b_EXV_PressSens_FltDtct
      VeVLDR_b_EXV_PressElctrFlt_FltDtct: variation-point={short-label=vpVeVLDR_b_EXV_PressElctrFlt_FltDtct, sw-syscond=1}, nonqueued-receiver-com-spec{data-element=Value, init-value=0}, required-interface=VeVLDR_b_EXV_PressElctrFlt_FltDtct
      VeRCVR_e_CPV_Valve_Stuck_State: variation-point={short-label=vpVeRCVR_e_CPV_Valve_Stuck_State, sw-syscond=1}, nonqueued-receiver-com-spec{data-element=Value, init-value=CeRCVR_e_Closed}, required-interface=VeRCVR_e_CPV_Valve_Stuck_State
      VeDMAB_y_StatusByte_AC_RefrigTempSnsrCPerf: variation-point={short-label=vpVeDMAB_y_StatusByte_AC_RefrigTempSnsrCPerf, sw-syscond=1}, nonqueued-receiver-com-spec{data-element=Value, init-value=0}, required-interface=VeDMAB_y_StatusByte_AC_RefrigTempSnsrCPerf
      VeDMAB_y_StatusByte_LostCommACRefrigExpVlvActC: variation-point={short-label=vpVeDMAB_y_StatusByte_LostCommACRefrigExpVlvActC, sw-syscond=1}, nonqueued-receiver-com-spec{data-element=Value, init-value=0}, required-interface=VeDMAB_y_StatusByte_LostCommACRefrigExpVlvActC
      VeVLDR_b_EEXV_TempElctrFlt_FltDtct: variation-point={short-label=vpVeVLDR_b_EEXV_TempElctrFlt_FltDtct, sw-syscond=1}, nonqueued-receiver-com-spec{data-element=Value, init-value=0}, required-interface=VeVLDR_b_EEXV_TempElctrFlt_FltDtct
      VeVLDR_b_EEXV_PressElctrFlt_FltDtct: variation-point={short-label=vpVeVLDR_b_EEXV_PressElctrFlt_FltDtct, sw-syscond=1}, nonqueued-receiver-com-spec{data-element=Value, init-value=0}, required-interface=VeVLDR_b_EEXV_PressElctrFlt_FltDtct
      VeVLDR_b_EEXV_PressSens_FltDtct: variation-point={short-label=vpVeVLDR_b_EEXV_PressSens_FltDtct, sw-syscond=1}, nonqueued-receiver-com-spec{data-element=Value, init-value=0}, required-interface=VeVLDR_b_EEXV_PressSens_FltDtct
      VeVLDR_b_EEXV_PerfDiag_FltDtct: variation-point={short-label=vpVeVLDR_b_EEXV_PerfDiag_FltDtct, sw-syscond=1}, nonqueued-receiver-com-spec{data-element=Value, init-value=0}, required-interface=VeVLDR_b_EEXV_PerfDiag_FltDtct
      VeDMAB_y_StatusByte_LostCommACRefrigExpVlvActD: variation-point={short-label=vpVeDMAB_y_StatusByte_LostCommACRefrigExpVlvActD, sw-syscond=1}, nonqueued-receiver-com-spec{data-element=Value, init-value=0}, required-interface=VeDMAB_y_StatusByte_LostCommACRefrigExpVlvActD
      VeDMAB_y_StatusByte_AC_RefrigTempSnsr4CktPerf: variation-point={short-label=vpVeDMAB_y_StatusByte_AC_RefrigTempSnsr4CktPerf, sw-syscond=1}, nonqueued-receiver-com-spec{data-element=Value, init-value=0}, required-interface=VeDMAB_y_StatusByte_AC_RefrigTempSnsr4CktPerf
      VeDMAB_y_StatusByte_AC_RefrigTempSnsr5CktPerf: variation-point={short-label=vpVeDMAB_y_StatusByte_AC_RefrigTempSnsr5CktPerf, sw-syscond=1}, nonqueued-receiver-com-spec{data-element=Value, init-value=0}, required-interface=VeDMAB_y_StatusByte_AC_RefrigTempSnsr5CktPerf
      VeVLDR_b_OEXV_PressElctrFlt_FltDtct: variation-point={short-label=vpVeVLDR_b_OEXV_PressElctrFlt_FltDtct, sw-syscond=1}, nonqueued-receiver-com-spec{data-element=Value, init-value=0}, required-interface=VeVLDR_b_OEXV_PressElctrFlt_FltDtct
      VeVLDR_b_OEXV_PressSens_FltDtct: variation-point={short-label=vpVeVLDR_b_OEXV_PressSens_FltDtct, sw-syscond=1}, nonqueued-receiver-com-spec{data-element=Value, init-value=0}, required-interface=VeVLDR_b_OEXV_PressSens_FltDtct
      VeVLDR_b_OEXV_PerfDiag_FltDtct: variation-point={short-label=vpVeVLDR_b_OEXV_PerfDiag_FltDtct, sw-syscond=1}, nonqueued-receiver-com-spec{data-element=Value, init-value=0}, required-interface=VeVLDR_b_OEXV_PerfDiag_FltDtct
      VeRCVR_e_HTL_Valve_Stuck_State: variation-point={short-label=vpVeRCVR_e_HTL_Valve_Stuck_State, sw-syscond=1}, nonqueued-receiver-com-spec{data-element=Value, init-value=CeRCVR_e_Closed}, required-interface=VeRCVR_e_HTL_Valve_Stuck_State
      VeRCVR_e_HtrCoreBypVlv_Stuck_State: variation-point={short-label=vpVeRCVR_e_HtrCoreBypVlv_Stuck_State, sw-syscond=1}, nonqueued-receiver-com-spec{data-element=Value, init-value=CeRCVR_e_Closed}, required-interface=VeRCVR_e_HtrCoreBypVlv_Stuck_State
    31 x provide port:
      VeTPCR_t_BatPerWU_ThrmlCond_Timer: variation-point={short-label=vpVeTPCR_t_BatPerWU_ThrmlCond_Timer, sw-syscond=1}, nonqueued-sender-com-spec{data-element=Value, init-value=0}, provided-interface=VeTPCR_t_BatPerWU_ThrmlCond_Timer
      VeTPCR_b_PeriodWup_Msg2: variation-point={short-label=vpVeTPCR_b_PeriodWup_Msg2, sw-syscond=1}, nonqueued-sender-com-spec{data-element=Value, init-value=0}, provided-interface=VeTPCR_b_PeriodWup_Msg2
      VeTPCR_e_CabinPreCondReqStat: variation-point={short-label=vpVeTPCR_e_CabinPreCondReqStat, sw-syscond=1}, nonqueued-sender-com-spec{data-element=Value, init-value=CeTPCR_e_CabinPrec_Dflt}, provided-interface=VeTPCR_e_CabinPreCondReqStat
      VeTPCR_b_RSA_BatCrit_Msg3: variation-point={short-label=vpVeTPCR_b_RSA_BatCrit_Msg3, sw-syscond=1}, nonqueued-sender-com-spec{data-element=Value, init-value=0}, provided-interface=VeTPCR_b_RSA_BatCrit_Msg3
      VeTPCR_b_RdyForShtDwn: variation-point={short-label=vpVeTPCR_b_RdyForShtDwn, sw-syscond=1}, nonqueued-sender-com-spec{data-element=Value, init-value=0}, provided-interface=VeTPCR_b_RdyForShtDwn
      VeTPCR_e_ThrmPerWup_State: variation-point={short-label=vpVeTPCR_e_ThrmPerWup_State, sw-syscond=1}, nonqueued-sender-com-spec{data-element=Value, init-value=CeTPCR_e_NoWup_Set_ShortTim_RS_Denied}, provided-interface=VeTPCR_e_ThrmPerWup_State
      VeTPCR_e_PerWup_BattEngCond_State: variation-point={short-label=vpVeTPCR_e_PerWup_BattEngCond_State, sw-syscond=1}, nonqueued-sender-com-spec{data-element=Value, init-value=CeTPCR_e_NoneOfEngBatt_Cond}, provided-interface=VeTPCR_e_PerWup_BattEngCond_State
      VeTPCR_dT_PerWpCond_EngTmpErr: variation-point={short-label=vpVeTPCR_dT_PerWpCond_EngTmpErr, sw-syscond=1}, nonqueued-sender-com-spec{data-element=Value, init-value=0}, provided-interface=VeTPCR_dT_PerWpCond_EngTmpErr
      VeTPCR_dT_PerWpCond_BatTmpErr: variation-point={short-label=vpVeTPCR_dT_PerWpCond_BatTmpErr, sw-syscond=1}, nonqueued-sender-com-spec{data-element=Value, init-value=0}, provided-interface=VeTPCR_dT_PerWpCond_BatTmpErr
      VeTPCR_b_HtrOrEAC_FltRawPrst: variation-point={short-label=vpVeTPCR_b_HtrOrEAC_FltRawPrst, sw-syscond=1}, nonqueued-sender-com-spec{data-element=Value, init-value=0}, provided-interface=VeTPCR_b_HtrOrEAC_FltRawPrst
      VeTPCR_t_SC_PrecTimer: variation-point={short-label=vpVeTPCR_t_SC_PrecTimer, sw-syscond=1}, nonqueued-sender-com-spec{data-element=Value, init-value=0}, provided-interface=VeTPCR_t_SC_PrecTimer
      VeTPCR_e_SC_WakeUp: variation-point={short-label=vpVeTPCR_e_SC_WakeUp, sw-syscond=1}, nonqueued-sender-com-spec{data-element=Value, init-value=CeTPCR_e_SC_NotAwake}, provided-interface=VeTPCR_e_SC_WakeUp
      VeTPCR_t_TimeToDeparture: variation-point={short-label=vpVeTPCR_t_TimeToDeparture, sw-syscond=1}, nonqueued-sender-com-spec{data-element=Value, init-value=0}, provided-interface=VeTPCR_t_TimeToDeparture
      VeTPCR_b_CabPrecDny_BattCond: variation-point={short-label=vpVeTPCR_b_CabPrecDny_BattCond, sw-syscond=1}, nonqueued-sender-com-spec{data-element=Value, init-value=0}, provided-interface=VeTPCR_b_CabPrecDny_BattCond
      VeTPCR_e_CabReqSt_Msgs: variation-point={short-label=vpVeTPCR_e_CabReqSt_Msgs, sw-syscond=1}, nonqueued-sender-com-spec{data-element=Value, init-value=CeTPCR_e_CabinPrec_Dflt}, provided-interface=VeTPCR_e_CabReqSt_Msgs
      VeTPCR_e_KeepHotColdSts: variation-point={short-label=vpVeTPCR_e_KeepHotColdSts, sw-syscond=1}, nonqueued-sender-com-spec{data-element=Value, init-value=CeTPCR_e_NotActive}, provided-interface=VeTPCR_e_KeepHotColdSts
      VeTPCR_e_KeepHotColdHMI: variation-point={short-label=vpVeTPCR_e_KeepHotColdHMI, sw-syscond=1}, nonqueued-sender-com-spec{data-element=Value, init-value=CeTPCR_e_NoRequest}, provided-interface=VeTPCR_e_KeepHotColdHMI
      VeTPCR_b_KeyOffCabCond: variation-point={short-label=vpVeTPCR_b_KeyOffCabCond, sw-syscond=1}, nonqueued-sender-com-spec{data-element=Value, init-value=0}, provided-interface=VeTPCR_b_KeyOffCabCond
      VeTPCR_e_ProactiveCondStat: variation-point={short-label=vpVeTPCR_e_ProactiveCondStat, sw-syscond=1}, nonqueued-sender-com-spec{data-element=Value, init-value=CeTPCR_e_ProactiveCondOff}, provided-interface=VeTPCR_e_ProactiveCondStat
      VeTPCR_e_ProactiveCondMode: variation-point={short-label=vpVeTPCR_e_ProactiveCondMode, sw-syscond=1}, nonqueued-sender-com-spec{data-element=Value, init-value=CeTPCR_e_NoProactiveCond}, provided-interface=VeTPCR_e_ProactiveCondMode
      VeTPCR_b_ClimateFail: variation-point={short-label=vpVeTPCR_b_ClimateFail, sw-syscond=1}, nonqueued-sender-com-spec{data-element=Value, init-value=0}, provided-interface=VeTPCR_b_ClimateFail
      VeTPCR_e_RacePrepState: variation-point={short-label=vpVeTPCR_e_RacePrepState, sw-syscond=1}, nonqueued-sender-com-spec{data-element=Value, init-value=CeTPCR_e_NotRacePrep}, provided-interface=VeTPCR_e_RacePrepState
      VeTPCR_b_RacePrepAmbCheck: variation-point={short-label=vpVeTPCR_b_RacePrepAmbCheck, sw-syscond=1}, nonqueued-sender-com-spec{data-element=Value, init-value=0}, provided-interface=VeTPCR_b_RacePrepAmbCheck
      VeTPCR_T_RacePrep_ModulOverTmp: variation-point={short-label=vpVeTPCR_T_RacePrep_ModulOverTmp, sw-syscond=1}, nonqueued-sender-com-spec{data-element=Value, init-value=0}, provided-interface=VeTPCR_T_RacePrep_ModulOverTmp
      VeTPCR_T_RacePrep_ModulUnderTmp: variation-point={short-label=vpVeTPCR_T_RacePrep_ModulUnderTmp, sw-syscond=1}, nonqueued-sender-com-spec{data-element=Value, init-value=0}, provided-interface=VeTPCR_T_RacePrep_ModulUnderTmp
      VeTPCR_T_RacePrep_SOCTrgt: variation-point={short-label=vpVeTPCR_T_RacePrep_SOCTrgt, sw-syscond=1}, nonqueued-sender-com-spec{data-element=Value, init-value=0}, provided-interface=VeTPCR_T_RacePrep_SOCTrgt
      VeTPCR_t_RacePrep_DeacTime: variation-point={short-label=vpVeTPCR_t_RacePrep_DeacTime, sw-syscond=1}, nonqueued-sender-com-spec{data-element=Value, init-value=0}, provided-interface=VeTPCR_t_RacePrep_DeacTime
      VeTPCR_b_RacePrepEVSysStatus: variation-point={short-label=vpVeTPCR_b_RacePrepEVSysStatus, sw-syscond=1}, nonqueued-sender-com-spec{data-element=Value, init-value=0}, provided-interface=VeTPCR_b_RacePrepEVSysStatus
      VeTPCR_T_RacePrep_ThrmlTrgt: variation-point={short-label=vpVeTPCR_T_RacePrep_ThrmlTrgt, sw-syscond=1}, nonqueued-sender-com-spec{data-element=Value, init-value=0}, provided-interface=VeTPCR_T_RacePrep_ThrmlTrgt
      VeTPCR_T_CabinTempSetPt: variation-point={short-label=vpVeTPCR_T_CabinTempSetPt, sw-syscond=1}, nonqueued-sender-com-spec{data-element=Value, init-value=0}, provided-interface=VeTPCR_T_CabinTempSetPt
      VeTPCR_I_RacePrepCurrentLim: variation-point={short-label=vpVeTPCR_I_RacePrepCurrentLim, sw-syscond=1}, nonqueued-sender-com-spec{data-element=Value, init-value=0}, provided-interface=VeTPCR_I_RacePrepCurrentLim
    6 x require port:
      NeTPCR_b_RS_CabPrecDeny_Prev_Rx: nv-require-com-spec{init-value=0, variable=NeTPCR_b_RS_CabPrecDeny_Prev}, required-interface=NeTPCR_b_RS_CabPrecDeny_Prev
      NeTPCR_b_HoldCabPrecFailLtch_Rx: nv-require-com-spec{init-value=0, variable=NeTPCR_b_HoldCabPrecFailLtch}, required-interface=NeTPCR_b_HoldCabPrecFailLtch
      EeTPCR_e_HoldClusterMsg_Rx: nv-require-com-spec{init-value=0, variable=EeTPCR_e_HoldClusterMsg}, required-interface=EeTPCR_e_HoldClusterMsg
      EeTPCR_e_HoldClusterMsg_KHC_Rx: nv-require-com-spec{init-value=0, variable=EeTPCR_e_HoldClusterMsg_KHC}, required-interface=EeTPCR_e_HoldClusterMsg_KHC
      NeTPCR_Pct_WupSOC_Rx: nv-require-com-spec{init-value=60, variable=NeTPCR_Pct_WupSOC}, required-interface=NeTPCR_Pct_WupSOC
      NeTPCR_b_12VloadShed_Rx: nv-require-com-spec{init-value=0, variable=NeTPCR_b_12VloadShed}, required-interface=NeTPCR_b_12VloadShed
    6 x provide port:
      NeTPCR_b_RS_CabPrecDeny_Prev: nv-provide-com-spec{ram-block-init-value=0, variable=NeTPCR_b_RS_CabPrecDeny_Prev}, provided-interface=NeTPCR_b_RS_CabPrecDeny_Prev
      NeTPCR_b_HoldCabPrecFailLtch: nv-provide-com-spec{ram-block-init-value=0, variable=NeTPCR_b_HoldCabPrecFailLtch}, provided-interface=NeTPCR_b_HoldCabPrecFailLtch
      EeTPCR_e_HoldClusterMsg: nv-provide-com-spec{ram-block-init-value=0, variable=EeTPCR_e_HoldClusterMsg}, provided-interface=EeTPCR_e_HoldClusterMsg
      EeTPCR_e_HoldClusterMsg_KHC: nv-provide-com-spec{ram-block-init-value=0, variable=EeTPCR_e_HoldClusterMsg_KHC}, provided-interface=EeTPCR_e_HoldClusterMsg_KHC
      NeTPCR_Pct_WupSOC: nv-provide-com-spec{ram-block-init-value=60, variable=NeTPCR_Pct_WupSOC}, provided-interface=NeTPCR_Pct_WupSOC
      NeTPCR_b_12VloadShed: nv-provide-com-spec{ram-block-init-value=0, variable=NeTPCR_b_12VloadShed}, provided-interface=NeTPCR_b_12VloadShed
    require port KeTHMR_e_TurtleMd_Dial: parameter-require-com-spec{init-value=CeDMDR_e_No_Turtle_Mode, parameter=KeTHMR_e_TurtleMd_Dial}, required-interface=KeTHMR_e_TurtleMd_Dial
    require port KeTHMR_b_TurtleMd_SelDial: parameter-require-com-spec{init-value=KeTHMR_b_TurtleMd_SelDial_KeTHMR_b_TurtleMd_SelDial:0, parameter=KeTHMR_b_TurtleMd_SelDial}, required-interface=KeTHMR_b_TurtleMd_SelDial
    behavior IB_TPCR: data-type-mapping=msADTtoIDTMapping, handle-termination-and-restart=NO-SUPPORT, included-data-type-set=data-type=TePLTR_e_BCMPreCondCabinReq
      timing event Event_MedTEH: start-on-event=TPCR_MedTEH, period=0.1
      init event Event_TPCR_ac_Init: start-on-event=TPCR_ac_Init
      init event Event_PwrOn: start-on-event=TPCR_PwrOn
      init event Event_PwrOff: start-on-event=TPCR_PwrOff
      4 x runnable:
        TPCR_ac_Init
          data-send-points:
            10 x access:
              OUT_VeTPCR_e_CabinPreCondReqStat_Value: accessed-variable=VeTPCR_e_CabinPreCondReqStat.Value, variation-point={short-label=vpOUT_VeTPCR_e_CabinPreCondReqStat_Value, sw-syscond=1}
              OUT_VeTPCR_e_ThrmPerWup_State_Value: accessed-variable=VeTPCR_e_ThrmPerWup_State.Value, variation-point={short-label=vpOUT_VeTPCR_e_ThrmPerWup_State_Value, sw-syscond=1}
              OUT_VeTPCR_e_PerWup_BattEngCond_State_Value: accessed-variable=VeTPCR_e_PerWup_BattEngCond_State.Value, variation-point={short-label=vpOUT_VeTPCR_e_PerWup_BattEngCond_State_Value, sw-syscond=1}
              OUT_VeTPCR_e_SC_WakeUp_Value: accessed-variable=VeTPCR_e_SC_WakeUp.Value, variation-point={short-label=vpOUT_VeTPCR_e_SC_WakeUp_Value, sw-syscond=1}
              OUT_VeTPCR_e_CabReqSt_Msgs_Value: accessed-variable=VeTPCR_e_CabReqSt_Msgs.Value, variation-point={short-label=vpOUT_VeTPCR_e_CabReqSt_Msgs_Value, sw-syscond=1}
              OUT_VeTPCR_e_KeepHotColdSts_Value: accessed-variable=VeTPCR_e_KeepHotColdSts.Value, variation-point={short-label=vpOUT_VeTPCR_e_KeepHotColdSts_Value, sw-syscond=1}
              OUT_VeTPCR_e_KeepHotColdHMI_Value: accessed-variable=VeTPCR_e_KeepHotColdHMI.Value, variation-point={short-label=vpOUT_VeTPCR_e_KeepHotColdHMI_Value, sw-syscond=1}
              OUT_VeTPCR_e_ProactiveCondStat_Value: accessed-variable=VeTPCR_e_ProactiveCondStat.Value, variation-point={short-label=vpOUT_VeTPCR_e_ProactiveCondStat_Value, sw-syscond=1}
              OUT_VeTPCR_e_ProactiveCondMode_Value: accessed-variable=VeTPCR_e_ProactiveCondMode.Value, variation-point={short-label=vpOUT_VeTPCR_e_ProactiveCondMode_Value, sw-syscond=1}
              OUT_VeTPCR_e_RacePrepState_Value: accessed-variable=VeTPCR_e_RacePrepState.Value, variation-point={short-label=vpOUT_VeTPCR_e_RacePrepState_Value, sw-syscond=1}
        TPCR_PwrOn
          data-receive-point-by-arguments:
            6 x access:
              IN_EeTPCR_e_HoldClusterMsg_KHC_Rx_EeTPCR_e_HoldClusterMsg_KHC: accessed-variable=EeTPCR_e_HoldClusterMsg_KHC_Rx.EeTPCR_e_HoldClusterMsg_KHC
              IN_EeTPCR_e_HoldClusterMsg_Rx_EeTPCR_e_HoldClusterMsg: accessed-variable=EeTPCR_e_HoldClusterMsg_Rx.EeTPCR_e_HoldClusterMsg
              IN_NeTPCR_Pct_WupSOC_Rx_NeTPCR_Pct_WupSOC: accessed-variable=NeTPCR_Pct_WupSOC_Rx.NeTPCR_Pct_WupSOC
              IN_NeTPCR_b_12VloadShed_Rx_NeTPCR_b_12VloadShed: accessed-variable=NeTPCR_b_12VloadShed_Rx.NeTPCR_b_12VloadShed
              IN_NeTPCR_b_HoldCabPrecFailLtch_Rx_NeTPCR_b_HoldCabPrecFailLtch: accessed-variable=NeTPCR_b_HoldCabPrecFailLtch_Rx.NeTPCR_b_HoldCabPrecFailLtch
              IN_NeTPCR_b_RS_CabPrecDeny_Prev_Rx_NeTPCR_b_RS_CabPrecDeny_Prev: accessed-variable=NeTPCR_b_RS_CabPrecDeny_Prev_Rx.NeTPCR_b_RS_CabPrecDeny_Prev
          data-send-points:
            31 x access:
              OUT_VeTPCR_t_BatPerWU_ThrmlCond_Timer_Value: accessed-variable=VeTPCR_t_BatPerWU_ThrmlCond_Timer.Value, variation-point={short-label=vpOUT_VeTPCR_t_BatPerWU_ThrmlCond_Timer_Value, sw-syscond=1}
              OUT_VeTPCR_b_PeriodWup_Msg2_Value: accessed-variable=VeTPCR_b_PeriodWup_Msg2.Value, variation-point={short-label=vpOUT_VeTPCR_b_PeriodWup_Msg2_Value, sw-syscond=1}
              OUT_VeTPCR_t_SC_PrecTimer_Value: accessed-variable=VeTPCR_t_SC_PrecTimer.Value, variation-point={short-label=vpOUT_VeTPCR_t_SC_PrecTimer_Value, sw-syscond=1}
              OUT_VeTPCR_e_SC_WakeUp_Value: accessed-variable=VeTPCR_e_SC_WakeUp.Value, variation-point={short-label=vpOUT_VeTPCR_e_SC_WakeUp_Value, sw-syscond=1}
              OUT_VeTPCR_t_TimeToDeparture_Value: accessed-variable=VeTPCR_t_TimeToDeparture.Value, variation-point={short-label=vpOUT_VeTPCR_t_TimeToDeparture_Value, sw-syscond=1}
              OUT_VeTPCR_b_CabPrecDny_BattCond_Value: accessed-variable=VeTPCR_b_CabPrecDny_BattCond.Value, variation-point={short-label=vpOUT_VeTPCR_b_CabPrecDny_BattCond_Value, sw-syscond=1}
              OUT_VeTPCR_e_CabReqSt_Msgs_Value: accessed-variable=VeTPCR_e_CabReqSt_Msgs.Value, variation-point={short-label=vpOUT_VeTPCR_e_CabReqSt_Msgs_Value, sw-syscond=1}
              OUT_VeTPCR_e_KeepHotColdSts_Value: accessed-variable=VeTPCR_e_KeepHotColdSts.Value, variation-point={short-label=vpOUT_VeTPCR_e_KeepHotColdSts_Value, sw-syscond=1}
              OUT_VeTPCR_e_KeepHotColdHMI_Value: accessed-variable=VeTPCR_e_KeepHotColdHMI.Value, variation-point={short-label=vpOUT_VeTPCR_e_KeepHotColdHMI_Value, sw-syscond=1}
              OUT_VeTPCR_b_KeyOffCabCond_Value: accessed-variable=VeTPCR_b_KeyOffCabCond.Value, variation-point={short-label=vpOUT_VeTPCR_b_KeyOffCabCond_Value, sw-syscond=1}
              OUT_VeTPCR_e_ProactiveCondStat_Value: accessed-variable=VeTPCR_e_ProactiveCondStat.Value, variation-point={short-label=vpOUT_VeTPCR_e_ProactiveCondStat_Value, sw-syscond=1}
              OUT_VeTPCR_e_ProactiveCondMode_Value: accessed-variable=VeTPCR_e_ProactiveCondMode.Value, variation-point={short-label=vpOUT_VeTPCR_e_ProactiveCondMode_Value, sw-syscond=1}
              OUT_VeTPCR_e_CabinPreCondReqStat_Value: accessed-variable=VeTPCR_e_CabinPreCondReqStat.Value, variation-point={short-label=vpOUT_VeTPCR_e_CabinPreCondReqStat_Value, sw-syscond=1}
              OUT_VeTPCR_b_ClimateFail_Value: accessed-variable=VeTPCR_b_ClimateFail.Value, variation-point={short-label=vpOUT_VeTPCR_b_ClimateFail_Value, sw-syscond=1}
              OUT_VeTPCR_b_RSA_BatCrit_Msg3_Value: accessed-variable=VeTPCR_b_RSA_BatCrit_Msg3.Value, variation-point={short-label=vpOUT_VeTPCR_b_RSA_BatCrit_Msg3_Value, sw-syscond=1}
              OUT_VeTPCR_b_RdyForShtDwn_Value: accessed-variable=VeTPCR_b_RdyForShtDwn.Value, variation-point={short-label=vpOUT_VeTPCR_b_RdyForShtDwn_Value, sw-syscond=1}
              OUT_VeTPCR_e_ThrmPerWup_State_Value: accessed-variable=VeTPCR_e_ThrmPerWup_State.Value, variation-point={short-label=vpOUT_VeTPCR_e_ThrmPerWup_State_Value, sw-syscond=1}
              OUT_VeTPCR_e_PerWup_BattEngCond_State_Value: accessed-variable=VeTPCR_e_PerWup_BattEngCond_State.Value, variation-point={short-label=vpOUT_VeTPCR_e_PerWup_BattEngCond_State_Value, sw-syscond=1}
              OUT_VeTPCR_dT_PerWpCond_EngTmpErr_Value: accessed-variable=VeTPCR_dT_PerWpCond_EngTmpErr.Value, variation-point={short-label=vpOUT_VeTPCR_dT_PerWpCond_EngTmpErr_Value, sw-syscond=1}
              OUT_VeTPCR_dT_PerWpCond_BatTmpErr_Value: accessed-variable=VeTPCR_dT_PerWpCond_BatTmpErr.Value, variation-point={short-label=vpOUT_VeTPCR_dT_PerWpCond_BatTmpErr_Value, sw-syscond=1}
              OUT_VeTPCR_b_HtrOrEAC_FltRawPrst_Value: accessed-variable=VeTPCR_b_HtrOrEAC_FltRawPrst.Value, variation-point={short-label=vpOUT_VeTPCR_b_HtrOrEAC_FltRawPrst_Value, sw-syscond=1}
              OUT_VeTPCR_e_RacePrepState_Value: accessed-variable=VeTPCR_e_RacePrepState.Value, variation-point={short-label=vpOUT_VeTPCR_e_RacePrepState_Value, sw-syscond=1}
              OUT_VeTPCR_b_RacePrepAmbCheck_Value: accessed-variable=VeTPCR_b_RacePrepAmbCheck.Value, variation-point={short-label=vpOUT_VeTPCR_b_RacePrepAmbCheck_Value, sw-syscond=1}
              OUT_VeTPCR_T_RacePrep_ModulUnderTmp_Value: accessed-variable=VeTPCR_T_RacePrep_ModulUnderTmp.Value, variation-point={short-label=vpOUT_VeTPCR_T_RacePrep_ModulUnderTmp_Value, sw-syscond=1}
              OUT_VeTPCR_T_RacePrep_ModulOverTmp_Value: accessed-variable=VeTPCR_T_RacePrep_ModulOverTmp.Value, variation-point={short-label=vpOUT_VeTPCR_T_RacePrep_ModulOverTmp_Value, sw-syscond=1}
              OUT_VeTPCR_T_RacePrep_SOCTrgt_Value: accessed-variable=VeTPCR_T_RacePrep_SOCTrgt.Value, variation-point={short-label=vpOUT_VeTPCR_T_RacePrep_SOCTrgt_Value, sw-syscond=1}
              OUT_VeTPCR_b_RacePrepEVSysStatus_Value: accessed-variable=VeTPCR_b_RacePrepEVSysStatus.Value, variation-point={short-label=vpOUT_VeTPCR_b_RacePrepEVSysStatus_Value, sw-syscond=1}
              OUT_VeTPCR_T_RacePrep_ThrmlTrgt_Value: accessed-variable=VeTPCR_T_RacePrep_ThrmlTrgt.Value, variation-point={short-label=vpOUT_VeTPCR_T_RacePrep_ThrmlTrgt_Value, sw-syscond=1}
              OUT_VeTPCR_t_RacePrep_DeacTime_Value: accessed-variable=VeTPCR_t_RacePrep_DeacTime.Value, variation-point={short-label=vpOUT_VeTPCR_t_RacePrep_DeacTime_Value, sw-syscond=1}
              OUT_VeTPCR_T_CabinTempSetPt_Value: accessed-variable=VeTPCR_T_CabinTempSetPt.Value, variation-point={short-label=vpOUT_VeTPCR_T_CabinTempSetPt_Value, sw-syscond=1}
              OUT_VeTPCR_I_RacePrepCurrentLim_Value: accessed-variable=VeTPCR_I_RacePrepCurrentLim.Value, variation-point={short-label=vpOUT_VeTPCR_I_RacePrepCurrentLim_Value, sw-syscond=1}
        TPCR_MedTEH: variation-point={short-label=vpTPCR_MedTEH, sw-syscond=1}
          data-receive-point-by-arguments:
            162 x access:
              IN_VeAATR_T_EstAmbAirTemp_Value: accessed-variable=VeAATR_T_EstAmbAirTemp.Value, variation-point={short-label=vpIN_VeAATR_T_EstAmbAirTemp_Value, sw-syscond=1}
              IN_VeAATR_b_EstAmbAirTempFA_Value: accessed-variable=VeAATR_b_EstAmbAirTempFA.Value, variation-point={short-label=vpIN_VeAATR_b_EstAmbAirTempFA_Value, sw-syscond=1}
              IN_VeBPCR_Pct_HV_BatPackSOC_Arb_Value: accessed-variable=VeBPCR_Pct_HV_BatPackSOC_Arb.Value, variation-point={short-label=vpIN_VeBPCR_Pct_HV_BatPackSOC_Arb_Value, sw-syscond=1}
              IN_VeBPCR_b_BPCM_LOC_BCP_FA_Value: accessed-variable=VeBPCR_b_BPCM_LOC_BCP_FA.Value, variation-point={short-label=vpIN_VeBPCR_b_BPCM_LOC_BCP_FA_Value, sw-syscond=1}
              IN_VeBPCR_b_BPCM_LOC_BatClntHtr_FA_Value: accessed-variable=VeBPCR_b_BPCM_LOC_BatClntHtr_FA.Value, variation-point={short-label=vpIN_VeBPCR_b_BPCM_LOC_BatClntHtr_FA_Value, sw-syscond=1}
              IN_VeBPCR_e_BPCM_LOC_BCP_Value: accessed-variable=VeBPCR_e_BPCM_LOC_BCP.Value, variation-point={short-label=vpIN_VeBPCR_e_BPCM_LOC_BCP_Value, sw-syscond=1}
              IN_VeBPCR_e_BPCM_LOC_BatClntHtr_Value: accessed-variable=VeBPCR_e_BPCM_LOC_BatClntHtr.Value, variation-point={short-label=vpIN_VeBPCR_e_BPCM_LOC_BatClntHtr_Value, sw-syscond=1}
              IN_VeBPCR_e_HV_BatCntctrStat_Value: accessed-variable=VeBPCR_e_HV_BatCntctrStat.Value, variation-point={short-label=vpIN_VeBPCR_e_HV_BatCntctrStat_Value, sw-syscond=1}
              IN_VeBTRR_T_BTISBTIS2_Max_Value: accessed-variable=VeBTRR_T_BTISBTIS2_Max.Value, variation-point={short-label=vpIN_VeBTRR_T_BTISBTIS2_Max_Value, sw-syscond=1}
              IN_VeBTRR_T_CellTempAvgUsed_Value: accessed-variable=VeBTRR_T_CellTempAvgUsed.Value, variation-point={short-label=vpIN_VeBTRR_T_CellTempAvgUsed_Value, sw-syscond=1}
              IN_VeBTRR_T_CellTempMaxUsed_Value: accessed-variable=VeBTRR_T_CellTempMaxUsed.Value, variation-point={short-label=vpIN_VeBTRR_T_CellTempMaxUsed_Value, sw-syscond=1}
              IN_VeBTRR_T_CellTempMinUsed_Value: accessed-variable=VeBTRR_T_CellTempMinUsed.Value, variation-point={short-label=vpIN_VeBTRR_T_CellTempMinUsed_Value, sw-syscond=1}
              IN_VeBTRR_dT_CellOverTemp_Value: accessed-variable=VeBTRR_dT_CellOverTemp.Value, variation-point={short-label=vpIN_VeBTRR_dT_CellOverTemp_Value, sw-syscond=1}
              IN_VeBTRR_dT_CellUnderTemp_Value: accessed-variable=VeBTRR_dT_CellUnderTemp.Value, variation-point={short-label=vpIN_VeBTRR_dT_CellUnderTemp_Value, sw-syscond=1}
              IN_VeBTRR_e_HV_BatTempCrit_CondState_New_Value: accessed-variable=VeBTRR_e_HV_BatTempCrit_CondState_New.Value, variation-point={short-label=vpIN_VeBTRR_e_HV_BatTempCrit_CondState_New_Value, sw-syscond=1}
              IN_VeCITR_P_ChargingDestinationPwr_Value: accessed-variable=VeCITR_P_ChargingDestinationPwr.Value, variation-point={short-label=vpIN_VeCITR_P_ChargingDestinationPwr_Value, sw-syscond=1}
              IN_VeCITR_b_ChargingDestinationPwr_FA_Value: accessed-variable=VeCITR_b_ChargingDestinationPwr_FA.Value, variation-point={short-label=vpIN_VeCITR_b_ChargingDestinationPwr_FA_Value, sw-syscond=1}
              IN_VeCITR_b_DistanceToCharge_FA_Value: accessed-variable=VeCITR_b_DistanceToCharge_FA.Value, variation-point={short-label=vpIN_VeCITR_b_DistanceToCharge_FA_Value, sw-syscond=1}
              IN_VeCITR_b_TimeToCharge_FA_Value: accessed-variable=VeCITR_b_TimeToCharge_FA.Value, variation-point={short-label=vpIN_VeCITR_b_TimeToCharge_FA_Value, sw-syscond=1}
              IN_VeCITR_e_FOTA_Install_Type_Value: accessed-variable=VeCITR_e_FOTA_Install_Type.Value, variation-point={short-label=vpIN_VeCITR_e_FOTA_Install_Type_Value, sw-syscond=1}
              IN_VeCITR_l_DistanceToCharge_Value: accessed-variable=VeCITR_l_DistanceToCharge.Value, variation-point={short-label=vpIN_VeCITR_l_DistanceToCharge_Value, sw-syscond=1}
              IN_VeCITR_t_TimeToCharge_Value: accessed-variable=VeCITR_t_TimeToCharge.Value, variation-point={short-label=vpIN_VeCITR_t_TimeToCharge_Value, sw-syscond=1}
              IN_VeCSVR_v_VehSpd_Value: accessed-variable=VeCSVR_v_VehSpd.Value, variation-point={short-label=vpIN_VeCSVR_v_VehSpd_Value, sw-syscond=1}
              IN_VeCTRR_b_HVAC_HeatReq_Value: accessed-variable=VeCTRR_b_HVAC_HeatReq.Value, variation-point={short-label=vpIN_VeCTRR_b_HVAC_HeatReq_Value, sw-syscond=1}
              IN_VeDMAB_y_StatusByte_AC_RefrigPresSnsrAHi_Value: accessed-variable=VeDMAB_y_StatusByte_AC_RefrigPresSnsrAHi.Value, variation-point={short-label=vpIN_VeDMAB_y_StatusByte_AC_RefrigPresSnsrAHi_Value, sw-syscond=1}
              IN_VeDMAB_y_StatusByte_AC_RefrigPresSnsrALo_Value: accessed-variable=VeDMAB_y_StatusByte_AC_RefrigPresSnsrALo.Value, variation-point={short-label=vpIN_VeDMAB_y_StatusByte_AC_RefrigPresSnsrALo_Value, sw-syscond=1}
              IN_VeDMAB_y_StatusByte_AC_RefrigPresSnsrAPerf_Value: accessed-variable=VeDMAB_y_StatusByte_AC_RefrigPresSnsrAPerf.Value, variation-point={short-label=vpIN_VeDMAB_y_StatusByte_AC_RefrigPresSnsrAPerf_Value, sw-syscond=1}
              IN_VeDMAB_y_StatusByte_AC_RefrigTempSnsr4CktPerf_Value: accessed-variable=VeDMAB_y_StatusByte_AC_RefrigTempSnsr4CktPerf.Value, variation-point={short-label=vpIN_VeDMAB_y_StatusByte_AC_RefrigTempSnsr4CktPerf_Value, sw-syscond=1}
              IN_VeDMAB_y_StatusByte_AC_RefrigTempSnsr5CktPerf_Value: accessed-variable=VeDMAB_y_StatusByte_AC_RefrigTempSnsr5CktPerf.Value, variation-point={short-label=vpIN_VeDMAB_y_StatusByte_AC_RefrigTempSnsr5CktPerf_Value, sw-syscond=1}
              IN_VeDMAB_y_StatusByte_AC_RefrigTempSnsrCPerf_Value: accessed-variable=VeDMAB_y_StatusByte_AC_RefrigTempSnsrCPerf.Value, variation-point={short-label=vpIN_VeDMAB_y_StatusByte_AC_RefrigTempSnsrCPerf_Value, sw-syscond=1}
              IN_VeDMAB_y_StatusByte_BattCool_Value: accessed-variable=VeDMAB_y_StatusByte_BattCool.Value, variation-point={short-label=vpIN_VeDMAB_y_StatusByte_BattCool_Value, sw-syscond=1}
              IN_VeDMAB_y_StatusByte_BattCoolLvlLow_Value: accessed-variable=VeDMAB_y_StatusByte_BattCoolLvlLow.Value, variation-point={short-label=vpIN_VeDMAB_y_StatusByte_BattCoolLvlLow_Value, sw-syscond=1}
              IN_VeDMAB_y_StatusByte_BattCoolLvlSnsCkt_Value: accessed-variable=VeDMAB_y_StatusByte_BattCoolLvlSnsCkt.Value, variation-point={short-label=vpIN_VeDMAB_y_StatusByte_BattCoolLvlSnsCkt_Value, sw-syscond=1}
              IN_VeDMAB_y_StatusByte_BattCoolPmpATempSnsrPerf_Value: accessed-variable=VeDMAB_y_StatusByte_BattCoolPmpATempSnsrPerf.Value, variation-point={short-label=vpIN_VeDMAB_y_StatusByte_BattCoolPmpATempSnsrPerf_Value, sw-syscond=1}
              IN_VeDMAB_y_StatusByte_BattCoolPmpHtrBTempSnsrPerf_Value: accessed-variable=VeDMAB_y_StatusByte_BattCoolPmpHtrBTempSnsrPerf.Value, variation-point={short-label=vpIN_VeDMAB_y_StatusByte_BattCoolPmpHtrBTempSnsrPerf_Value, sw-syscond=1}
              IN_VeDMAB_y_StatusByte_BattCoolPmpOveSpd_Value: accessed-variable=VeDMAB_y_StatusByte_BattCoolPmpOveSpd.Value, variation-point={short-label=vpIN_VeDMAB_y_StatusByte_BattCoolPmpOveSpd_Value, sw-syscond=1}
              IN_VeDMAB_y_StatusByte_BattCoolPmpPerf_Value: accessed-variable=VeDMAB_y_StatusByte_BattCoolPmpPerf.Value, variation-point={short-label=vpIN_VeDMAB_y_StatusByte_BattCoolPmpPerf_Value, sw-syscond=1}
              IN_VeDMAB_y_StatusByte_BattHeat_Value: accessed-variable=VeDMAB_y_StatusByte_BattHeat.Value, variation-point={short-label=vpIN_VeDMAB_y_StatusByte_BattHeat_Value, sw-syscond=1}
              IN_VeDMAB_y_StatusByte_CT2_SnsrCktHi_Value: accessed-variable=VeDMAB_y_StatusByte_CT2_SnsrCktHi.Value, variation-point={short-label=vpIN_VeDMAB_y_StatusByte_CT2_SnsrCktHi_Value, sw-syscond=1}
              IN_VeDMAB_y_StatusByte_CT2_SnsrCktLo_Value: accessed-variable=VeDMAB_y_StatusByte_CT2_SnsrCktLo.Value, variation-point={short-label=vpIN_VeDMAB_y_StatusByte_CT2_SnsrCktLo_Value, sw-syscond=1}
              IN_VeDMAB_y_StatusByte_CT2_SnsrPerf_Value: accessed-variable=VeDMAB_y_StatusByte_CT2_SnsrPerf.Value, variation-point={short-label=vpIN_VeDMAB_y_StatusByte_CT2_SnsrPerf_Value, sw-syscond=1}
              IN_VeDMAB_y_StatusByte_CommBusOff_Value: accessed-variable=VeDMAB_y_StatusByte_CommBusOff.Value, variation-point={short-label=vpIN_VeDMAB_y_StatusByte_CommBusOff_Value, sw-syscond=1}
              IN_VeDMAB_y_StatusByte_CommBus_B_Off_Value: accessed-variable=VeDMAB_y_StatusByte_CommBus_B_Off.Value, variation-point={short-label=vpIN_VeDMAB_y_StatusByte_CommBus_B_Off_Value, sw-syscond=1}
              IN_VeDMAB_y_StatusByte_CoolHeaterAPerf_Value: accessed-variable=VeDMAB_y_StatusByte_CoolHeaterAPerf.Value, variation-point={short-label=vpIN_VeDMAB_y_StatusByte_CoolHeaterAPerf_Value, sw-syscond=1}
              IN_VeDMAB_y_StatusByte_CoolOutTempSnsCkt_Value: accessed-variable=VeDMAB_y_StatusByte_CoolOutTempSnsCkt.Value, variation-point={short-label=vpIN_VeDMAB_y_StatusByte_CoolOutTempSnsCkt_Value, sw-syscond=1}
              IN_VeDMAB_y_StatusByte_CoolPmpACtrlCktPerf_Value: accessed-variable=VeDMAB_y_StatusByte_CoolPmpACtrlCktPerf.Value, variation-point={short-label=vpIN_VeDMAB_y_StatusByte_CoolPmpACtrlCktPerf_Value, sw-syscond=1}
              IN_VeDMAB_y_StatusByte_CoolPmpATempSnsrPerf_Value: accessed-variable=VeDMAB_y_StatusByte_CoolPmpATempSnsrPerf.Value, variation-point={short-label=vpIN_VeDMAB_y_StatusByte_CoolPmpATempSnsrPerf_Value, sw-syscond=1}
              IN_VeDMAB_y_StatusByte_CoolantHeaterBPerf_Value: accessed-variable=VeDMAB_y_StatusByte_CoolantHeaterBPerf.Value, variation-point={short-label=vpIN_VeDMAB_y_StatusByte_CoolantHeaterBPerf_Value, sw-syscond=1}
              IN_VeDMAB_y_StatusByte_CoolantVlvA_Ckt_Value: accessed-variable=VeDMAB_y_StatusByte_CoolantVlvA_Ckt.Value, variation-point={short-label=vpIN_VeDMAB_y_StatusByte_CoolantVlvA_Ckt_Value, sw-syscond=1}
              IN_VeDMAB_y_StatusByte_CoolantVlvA_CktHi_Value: accessed-variable=VeDMAB_y_StatusByte_CoolantVlvA_CktHi.Value, variation-point={short-label=vpIN_VeDMAB_y_StatusByte_CoolantVlvA_CktHi_Value, sw-syscond=1}
              IN_VeDMAB_y_StatusByte_CoolantVlvA_CktLo_Value: accessed-variable=VeDMAB_y_StatusByte_CoolantVlvA_CktLo.Value, variation-point={short-label=vpIN_VeDMAB_y_StatusByte_CoolantVlvA_CktLo_Value, sw-syscond=1}
              IN_VeDMAB_y_StatusByte_CoolantVlvA_Perf_Value: accessed-variable=VeDMAB_y_StatusByte_CoolantVlvA_Perf.Value, variation-point={short-label=vpIN_VeDMAB_y_StatusByte_CoolantVlvA_Perf_Value, sw-syscond=1}
              IN_VeDMAB_y_StatusByte_CoolantVlvB_Ckt_Value: accessed-variable=VeDMAB_y_StatusByte_CoolantVlvB_Ckt.Value, variation-point={short-label=vpIN_VeDMAB_y_StatusByte_CoolantVlvB_Ckt_Value, sw-syscond=1}
              IN_VeDMAB_y_StatusByte_CoolantVlvB_CktHi_Value: accessed-variable=VeDMAB_y_StatusByte_CoolantVlvB_CktHi.Value, variation-point={short-label=vpIN_VeDMAB_y_StatusByte_CoolantVlvB_CktHi_Value, sw-syscond=1}
              IN_VeDMAB_y_StatusByte_CoolantVlvB_CktLo_Value: accessed-variable=VeDMAB_y_StatusByte_CoolantVlvB_CktLo.Value, variation-point={short-label=vpIN_VeDMAB_y_StatusByte_CoolantVlvB_CktLo_Value, sw-syscond=1}
              IN_VeDMAB_y_StatusByte_CoolantVlvB_StkClsd_Value: accessed-variable=VeDMAB_y_StatusByte_CoolantVlvB_StkClsd.Value, variation-point={short-label=vpIN_VeDMAB_y_StatusByte_CoolantVlvB_StkClsd_Value, sw-syscond=1}
              IN_VeDMAB_y_StatusByte_CoolantVlvB_StkOpn_Value: accessed-variable=VeDMAB_y_StatusByte_CoolantVlvB_StkOpn.Value, variation-point={short-label=vpIN_VeDMAB_y_StatusByte_CoolantVlvB_StkOpn_Value, sw-syscond=1}
              IN_VeDMAB_y_StatusByte_EACPerf_Value: accessed-variable=VeDMAB_y_StatusByte_EACPerf.Value, variation-point={short-label=vpIN_VeDMAB_y_StatusByte_EACPerf_Value, sw-syscond=1}
              IN_VeDMAB_y_StatusByte_ECH_TempIn_Value: accessed-variable=VeDMAB_y_StatusByte_ECH_TempIn.Value, variation-point={short-label=vpIN_VeDMAB_y_StatusByte_ECH_TempIn_Value, sw-syscond=1}
              IN_VeDMAB_y_StatusByte_ECH_TempOut_Value: accessed-variable=VeDMAB_y_StatusByte_ECH_TempOut.Value, variation-point={short-label=vpIN_VeDMAB_y_StatusByte_ECH_TempOut_Value, sw-syscond=1}
              IN_VeDMAB_y_StatusByte_EvapRefriShutoffCtrlCktFlt_Value: accessed-variable=VeDMAB_y_StatusByte_EvapRefriShutoffCtrlCktFlt.Value, variation-point={short-label=vpIN_VeDMAB_y_StatusByte_EvapRefriShutoffCtrlCktFlt_Value, sw-syscond=1}
              IN_VeDMAB_y_StatusByte_EvapRefriShutoffCtrlshrtBattFlt_Value: accessed-variable=VeDMAB_y_StatusByte_EvapRefriShutoffCtrlshrtBattFlt.Value, variation-point={short-label=vpIN_VeDMAB_y_StatusByte_EvapRefriShutoffCtrlshrtBattFlt_Value, sw-syscond=1}
              IN_VeDMAB_y_StatusByte_EvapRefrishutoffCtrlShrtGndFlt_Value: accessed-variable=VeDMAB_y_StatusByte_EvapRefrishutoffCtrlShrtGndFlt.Value, variation-point={short-label=vpIN_VeDMAB_y_StatusByte_EvapRefrishutoffCtrlShrtGndFlt_Value, sw-syscond=1}
              IN_VeDMAB_y_StatusByte_HB_CT_SnsrPerf_Value: accessed-variable=VeDMAB_y_StatusByte_HB_CT_SnsrPerf.Value, variation-point={short-label=vpIN_VeDMAB_y_StatusByte_HB_CT_SnsrPerf_Value, sw-syscond=1}
              IN_VeDMAB_y_StatusByte_HeatingElmntPerf_Value: accessed-variable=VeDMAB_y_StatusByte_HeatingElmntPerf.Value, variation-point={short-label=vpIN_VeDMAB_y_StatusByte_HeatingElmntPerf_Value, sw-syscond=1}
              IN_VeDMAB_y_StatusByte_HiSpdCANCommBus_Value: accessed-variable=VeDMAB_y_StatusByte_HiSpdCANCommBus.Value, variation-point={short-label=vpIN_VeDMAB_y_StatusByte_HiSpdCANCommBus_Value, sw-syscond=1}
              IN_VeDMAB_y_StatusByte_HighVolCabinAirHtrperf_Value: accessed-variable=VeDMAB_y_StatusByte_HighVolCabinAirHtrperf.Value, variation-point={short-label=vpIN_VeDMAB_y_StatusByte_HighVolCabinAirHtrperf_Value, sw-syscond=1}
              IN_VeDMAB_y_StatusByte_LIN{1..3}_BusOff_Value: accessed-variable=VeDMAB_y_StatusByte_LIN{1..3}_BusOff.Value, variation-point={short-label=vpIN_VeDMAB_y_StatusByte_LIN{1..3}_BusOff_Value, sw-syscond=1}
              IN_VeDMAB_y_StatusByte_LosCommBECM_A_Value: accessed-variable=VeDMAB_y_StatusByte_LosCommBECM_A.Value, variation-point={short-label=vpIN_VeDMAB_y_StatusByte_LosCommBECM_A_Value, sw-syscond=1}
              IN_VeDMAB_y_StatusByte_LosCommBECM_A_CANC11_Value: accessed-variable=VeDMAB_y_StatusByte_LosCommBECM_A_CANC11.Value, variation-point={short-label=vpIN_VeDMAB_y_StatusByte_LosCommBECM_A_CANC11_Value, sw-syscond=1}
              IN_VeDMAB_y_StatusByte_LostCommACRefrigExpVlvActA_Value: accessed-variable=VeDMAB_y_StatusByte_LostCommACRefrigExpVlvActA.Value, variation-point={short-label=vpIN_VeDMAB_y_StatusByte_LostCommACRefrigExpVlvActA_Value, sw-syscond=1}
              IN_VeDMAB_y_StatusByte_LostCommACRefrigExpVlvActC_Value: accessed-variable=VeDMAB_y_StatusByte_LostCommACRefrigExpVlvActC.Value, variation-point={short-label=vpIN_VeDMAB_y_StatusByte_LostCommACRefrigExpVlvActC_Value, sw-syscond=1}
              IN_VeDMAB_y_StatusByte_LostCommACRefrigExpVlvActD_Value: accessed-variable=VeDMAB_y_StatusByte_LostCommACRefrigExpVlvActD.Value, variation-point={short-label=vpIN_VeDMAB_y_StatusByte_LostCommACRefrigExpVlvActD_Value, sw-syscond=1}
              IN_VeDMAB_y_StatusByte_LostCommBCM_Value: accessed-variable=VeDMAB_y_StatusByte_LostCommBCM.Value, variation-point={short-label=vpIN_VeDMAB_y_StatusByte_LostCommBCM_Value, sw-syscond=1}
              IN_VeDMAB_y_StatusByte_LostCommCoolHtrA_Value: accessed-variable=VeDMAB_y_StatusByte_LostCommCoolHtrA.Value, variation-point={short-label=vpIN_VeDMAB_y_StatusByte_LostCommCoolHtrA_Value, sw-syscond=1}
              IN_VeDMAB_y_StatusByte_LostCommCoolPmpA_Value: accessed-variable=VeDMAB_y_StatusByte_LostCommCoolPmpA.Value, variation-point={short-label=vpIN_VeDMAB_y_StatusByte_LostCommCoolPmpA_Value, sw-syscond=1}
              IN_VeDMAB_y_StatusByte_LostCommEAC_Value: accessed-variable=VeDMAB_y_StatusByte_LostCommEAC.Value, variation-point={short-label=vpIN_VeDMAB_y_StatusByte_LostCommEAC_Value, sw-syscond=1}
              IN_VeDMAB_y_StatusByte_LostCommHB_CoolPmp_Value: accessed-variable=VeDMAB_y_StatusByte_LostCommHB_CoolPmp.Value, variation-point={short-label=vpIN_VeDMAB_y_StatusByte_LostCommHB_CoolPmp_Value, sw-syscond=1}
              IN_VeDMAB_y_StatusByte_LostCommHighVolCabinAirHtr_Value: accessed-variable=VeDMAB_y_StatusByte_LostCommHighVolCabinAirHtr.Value, variation-point={short-label=vpIN_VeDMAB_y_StatusByte_LostCommHighVolCabinAirHtr_Value, sw-syscond=1}
              IN_VeDMAB_y_StatusByte_ThrmlRlyCtrlCkt_Value: accessed-variable=VeDMAB_y_StatusByte_ThrmlRlyCtrlCkt.Value, variation-point={short-label=vpIN_VeDMAB_y_StatusByte_ThrmlRlyCtrlCkt_Value, sw-syscond=1}
              IN_VeDMDR_e_TurtleMdSts_Value: accessed-variable=VeDMDR_e_TurtleMdSts.Value, variation-point={short-label=vpIN_VeDMDR_e_TurtleMdSts_Value, sw-syscond=1}
              IN_VeENGR_T_EngCoolantTemp_Value: accessed-variable=VeENGR_T_EngCoolantTemp.Value, variation-point={short-label=vpIN_VeENGR_T_EngCoolantTemp_Value, sw-syscond=1}
              IN_VeENGR_b_ECT_Sgnl_Rcvd_Value: accessed-variable=VeENGR_b_ECT_Sgnl_Rcvd.Value, variation-point={short-label=vpIN_VeENGR_b_ECT_Sgnl_Rcvd_Value, sw-syscond=1}
              IN_VeENGR_b_ECT_SnsrFA_Value: accessed-variable=VeENGR_b_ECT_SnsrFA.Value, variation-point={short-label=vpIN_VeENGR_b_ECT_SnsrFA_Value, sw-syscond=1}
              IN_VeENGR_b_EngSysLowFuel_Value: accessed-variable=VeENGR_b_EngSysLowFuel.Value, variation-point={short-label=vpIN_VeENGR_b_EngSysLowFuel_Value, sw-syscond=1}
              IN_VeERER_l_EstRange_Value: accessed-variable=VeERER_l_EstRange.Value, variation-point={short-label=vpIN_VeERER_l_EstRange_Value, sw-syscond=1}
              IN_VeFSCR_b_HVFuncRejHdAjar_Value: accessed-variable=VeFSCR_b_HVFuncRejHdAjar.Value, variation-point={short-label=vpIN_VeFSCR_b_HVFuncRejHdAjar_Value, sw-syscond=1}
              IN_VeFSCR_b_RadFan_FltDtct_Value: accessed-variable=VeFSCR_b_RadFan_FltDtct.Value, variation-point={short-label=vpIN_VeFSCR_b_RadFan_FltDtct_Value, sw-syscond=1}
              IN_VeHCDR_b_HVC_Heater_FltDtct_Value: accessed-variable=VeHCDR_b_HVC_Heater_FltDtct.Value, variation-point={short-label=vpIN_VeHCDR_b_HVC_Heater_FltDtct_Value, sw-syscond=1}
              IN_VeHCDR_b_HV_Heater2_FltDtct_Value: accessed-variable=VeHCDR_b_HV_Heater2_FltDtct.Value, variation-point={short-label=vpIN_VeHCDR_b_HV_Heater2_FltDtct_Value, sw-syscond=1}
              IN_VeHCDR_e_BatteryThermalFault_Value: accessed-variable=VeHCDR_e_BatteryThermalFault.Value, variation-point={short-label=vpIN_VeHCDR_e_BatteryThermalFault_Value, sw-syscond=1}
              IN_VeHMIR_e_HEV_LMP_RQ_Value: accessed-variable=VeHMIR_e_HEV_LMP_RQ.Value, variation-point={short-label=vpIN_VeHMIR_e_HEV_LMP_RQ_Value, sw-syscond=1}
              IN_VeHPMR_b_PropSysActv_Value: accessed-variable=VeHPMR_b_PropSysActv.Value, variation-point={short-label=vpIN_VeHPMR_b_PropSysActv_Value, sw-syscond=1}
              IN_VeHTIR_e_HV_ElecClntHtr{2..4}_Sts_Value: accessed-variable=VeHTIR_e_HV_ElecClntHtr{2..4}_Sts.Value, variation-point={short-label=vpIN_VeHTIR_e_HV_ElecClntHtr{2..4}_Sts_Value, sw-syscond=1}
              IN_VeHTIR_e_HV_ElecClntHtr_Sts_Value: accessed-variable=VeHTIR_e_HV_ElecClntHtr_Sts.Value, variation-point={short-label=vpIN_VeHTIR_e_HV_ElecClntHtr_Sts_Value, sw-syscond=1}
              IN_VeHVTR_I_HV_BattCurrent_Value: accessed-variable=VeHVTR_I_HV_BattCurrent.Value, variation-point={short-label=vpIN_VeHVTR_I_HV_BattCurrent_Value, sw-syscond=1}
              IN_VeOBCR_P_AvalPwrForThmr_Value: accessed-variable=VeOBCR_P_AvalPwrForThmr.Value, variation-point={short-label=vpIN_VeOBCR_P_AvalPwrForThmr_Value, sw-syscond=1}
              IN_VeOBCR_P_Est_PowerBudget_Value: accessed-variable=VeOBCR_P_Est_PowerBudget.Value, variation-point={short-label=vpIN_VeOBCR_P_Est_PowerBudget_Value, sw-syscond=1}
              IN_VeOBCR_b_ChrgSysFault_Value: accessed-variable=VeOBCR_b_ChrgSysFault.Value, variation-point={short-label=vpIN_VeOBCR_b_ChrgSysFault_Value, sw-syscond=1}
              IN_VeOBCR_e_ChargingLevel_Value: accessed-variable=VeOBCR_e_ChargingLevel.Value, variation-point={short-label=vpIN_VeOBCR_e_ChargingLevel_Value, sw-syscond=1}
              IN_VeOBCR_e_ChargingSystemSts_Value: accessed-variable=VeOBCR_e_ChargingSystemSts.Value, variation-point={short-label=vpIN_VeOBCR_e_ChargingSystemSts_Value, sw-syscond=1}
              IN_VePLTR_b_HotEnablerReq_Value: accessed-variable=VePLTR_b_HotEnablerReq.Value, variation-point={short-label=vpIN_VePLTR_b_HotEnablerReq_Value, sw-syscond=1}
              IN_VePLTR_b_RmtVehStartReq_Value: accessed-variable=VePLTR_b_RmtVehStartReq.Value, variation-point={short-label=vpIN_VePLTR_b_RmtVehStartReq_Value, sw-syscond=1}
              IN_VePLTR_e_ShippingMode_Value: accessed-variable=VePLTR_e_ShippingMode.Value, variation-point={short-label=vpIN_VePLTR_e_ShippingMode_Value, sw-syscond=1}
              IN_VePMIR_b_HTAuxPumpDryRun_FA_Value: accessed-variable=VePMIR_b_HTAuxPumpDryRun_FA.Value, variation-point={short-label=vpIN_VePMIR_b_HTAuxPumpDryRun_FA_Value, sw-syscond=1}
              IN_VePMIR_b_LTActvPumpDryRun_FA_Value: accessed-variable=VePMIR_b_LTActvPumpDryRun_FA.Value, variation-point={short-label=vpIN_VePMIR_b_LTActvPumpDryRun_FA_Value, sw-syscond=1}
              IN_VePMIR_e_HTAuxPumpDryRun_Value: accessed-variable=VePMIR_e_HTAuxPumpDryRun.Value, variation-point={short-label=vpIN_VePMIR_e_HTAuxPumpDryRun_Value, sw-syscond=1}
              IN_VePMIR_e_LTActvPumpDryRun_Value: accessed-variable=VePMIR_e_LTActvPumpDryRun.Value, variation-point={short-label=vpIN_VePMIR_e_LTActvPumpDryRun_Value, sw-syscond=1}
              IN_VePMTR_b_ThrmlSystRly_EnblCmnd_Value: accessed-variable=VePMTR_b_ThrmlSystRly_EnblCmnd.Value, variation-point={short-label=vpIN_VePMTR_b_ThrmlSystRly_EnblCmnd_Value, sw-syscond=1}
              IN_VeRCVR_e_CPV_Valve_Stuck_State_Value: accessed-variable=VeRCVR_e_CPV_Valve_Stuck_State.Value, variation-point={short-label=vpIN_VeRCVR_e_CPV_Valve_Stuck_State_Value, sw-syscond=1}
              IN_VeRCVR_e_HTL_Valve_Stuck_State_Value: accessed-variable=VeRCVR_e_HTL_Valve_Stuck_State.Value, variation-point={short-label=vpIN_VeRCVR_e_HTL_Valve_Stuck_State_Value, sw-syscond=1}
              IN_VeRCVR_e_HtrCoreBypVlv_Stuck_State_Value: accessed-variable=VeRCVR_e_HtrCoreBypVlv_Stuck_State.Value, variation-point={short-label=vpIN_VeRCVR_e_HtrCoreBypVlv_Stuck_State_Value, sw-syscond=1}
              IN_VeSCPR_T_CabinTempSetPt_Value: accessed-variable=VeSCPR_T_CabinTempSetPt.Value, variation-point={short-label=vpIN_VeSCPR_T_CabinTempSetPt_Value, sw-syscond=1}
              IN_VeSCPR_b_BattCabinPriority_Value: accessed-variable=VeSCPR_b_BattCabinPriority.Value, variation-point={short-label=vpIN_VeSCPR_b_BattCabinPriority_Value, sw-syscond=1}
              IN_VeSCPR_e_SchCP_Allow_Value: accessed-variable=VeSCPR_e_SchCP_Allow.Value, variation-point={short-label=vpIN_VeSCPR_e_SchCP_Allow_Value, sw-syscond=1}
              IN_VeSCPR_t_TimeToDeparture_Value: accessed-variable=VeSCPR_t_TimeToDeparture.Value, variation-point={short-label=vpIN_VeSCPR_t_TimeToDeparture_Value, sw-syscond=1}
              IN_VeSRAR_b_Disable_RaceStart_Value: accessed-variable=VeSRAR_b_Disable_RaceStart.Value, variation-point={short-label=vpIN_VeSRAR_b_Disable_RaceStart_Value, sw-syscond=1}
              IN_VeSRAR_b_ThmlLoadShdActv_Value: accessed-variable=VeSRAR_b_ThmlLoadShdActv.Value, variation-point={short-label=vpIN_VeSRAR_b_ThmlLoadShdActv_Value, sw-syscond=1}
              IN_VeSSDR_b_HVBatPerWU12VChrg_Value: accessed-variable=VeSSDR_b_HVBatPerWU12VChrg.Value, variation-point={short-label=vpIN_VeSSDR_b_HVBatPerWU12VChrg_Value, sw-syscond=1}
              IN_VeSSDR_b_HVBatPerWUThermal_Value: accessed-variable=VeSSDR_b_HVBatPerWUThermal.Value, variation-point={short-label=vpIN_VeSSDR_b_HVBatPerWUThermal_Value, sw-syscond=1}
              IN_VeSSDR_b_HV_PerWU_CabinPre_Value: accessed-variable=VeSSDR_b_HV_PerWU_CabinPre.Value, variation-point={short-label=vpIN_VeSSDR_b_HV_PerWU_CabinPre_Value, sw-syscond=1}
              IN_VeSSDR_b_PrepareToShtdwn_Value: accessed-variable=VeSSDR_b_PrepareToShtdwn.Value, variation-point={short-label=vpIN_VeSSDR_b_PrepareToShtdwn_Value, sw-syscond=1}
              IN_VeSSDR_e_KeySts_Value: accessed-variable=VeSSDR_e_KeySts.Value, variation-point={short-label=vpIN_VeSSDR_e_KeySts_Value, sw-syscond=1}
              IN_VeTAIR_Pct_FrtBlwrCmd_Value: accessed-variable=VeTAIR_Pct_FrtBlwrCmd.Value, variation-point={short-label=vpIN_VeTAIR_Pct_FrtBlwrCmd_Value, sw-syscond=1}
              IN_VeTAIR_T_VhIntTmp_Value: accessed-variable=VeTAIR_T_VhIntTmp.Value, variation-point={short-label=vpIN_VeTAIR_T_VhIntTmp_Value, sw-syscond=1}
              IN_VeTAIR_b_ACCompReq_Value: accessed-variable=VeTAIR_b_ACCompReq.Value, variation-point={short-label=vpIN_VeTAIR_b_ACCompReq_Value, sw-syscond=1}
              IN_VeTAIR_b_VhIntTmp_FA_Value: accessed-variable=VeTAIR_b_VhIntTmp_FA.Value, variation-point={short-label=vpIN_VeTAIR_b_VhIntTmp_FA_Value, sw-syscond=1}
              IN_VeTHMR_T_MaxBattAllow_Value: accessed-variable=VeTHMR_T_MaxBattAllow.Value, variation-point={short-label=vpIN_VeTHMR_T_MaxBattAllow_Value, sw-syscond=1}
              IN_VeTHMR_T_PPCTIS_Arb_Value: accessed-variable=VeTHMR_T_PPCTIS_Arb.Value, variation-point={short-label=vpIN_VeTHMR_T_PPCTIS_Arb_Value, sw-syscond=1}
              IN_VeTHMR_b_BattAllowed_Value: accessed-variable=VeTHMR_b_BattAllowed.Value, variation-point={short-label=vpIN_VeTHMR_b_BattAllowed_Value, sw-syscond=1}
              IN_VeTHMR_b_DrvDrAjar_Value: accessed-variable=VeTHMR_b_DrvDrAjar.Value, variation-point={short-label=vpIN_VeTHMR_b_DrvDrAjar_Value, sw-syscond=1}
              IN_VeTHMR_e_BatThrmlSt_Value: accessed-variable=VeTHMR_e_BatThrmlSt.Value, variation-point={short-label=vpIN_VeTHMR_e_BatThrmlSt_Value, sw-syscond=1}
              IN_VeTHMR_e_CabCoolThermalState_Value: accessed-variable=VeTHMR_e_CabCoolThermalState.Value, variation-point={short-label=vpIN_VeTHMR_e_CabCoolThermalState_Value, sw-syscond=1}
              IN_VeTHMR_e_CabHeatThermalState_Value: accessed-variable=VeTHMR_e_CabHeatThermalState.Value, variation-point={short-label=vpIN_VeTHMR_e_CabHeatThermalState_Value, sw-syscond=1}
              IN_VeTIMR_e_RacePrep_Value: accessed-variable=VeTIMR_e_RacePrep.Value, variation-point={short-label=vpIN_VeTIMR_e_RacePrep_Value, sw-syscond=1}
              IN_VeTIMR_e_RacePrepRaceTypeSts_Value: accessed-variable=VeTIMR_e_RacePrepRaceTypeSts.Value, variation-point={short-label=vpIN_VeTIMR_e_RacePrepRaceTypeSts_Value, sw-syscond=1}
              IN_VeTMIR_T_ElecClntHtr_TmpIn_Value: accessed-variable=VeTMIR_T_ElecClntHtr_TmpIn.Value, variation-point={short-label=vpIN_VeTMIR_T_ElecClntHtr_TmpIn_Value, sw-syscond=1}
              IN_VeTMIR_b_ElecClntHtr_TmpIn_FA_Value: accessed-variable=VeTMIR_b_ElecClntHtr_TmpIn_FA.Value, variation-point={short-label=vpIN_VeTMIR_b_ElecClntHtr_TmpIn_FA_Value, sw-syscond=1}
              IN_VeTRIR_b_Comfort_EnblAct_Value: accessed-variable=VeTRIR_b_Comfort_EnblAct.Value, variation-point={short-label=vpIN_VeTRIR_b_Comfort_EnblAct_Value, sw-syscond=1}
              IN_VeTRIR_b_HtrCorClnt_TmpIn_FA_Value: accessed-variable=VeTRIR_b_HtrCorClnt_TmpIn_FA.Value, variation-point={short-label=vpIN_VeTRIR_b_HtrCorClnt_TmpIn_FA_Value, sw-syscond=1}
              IN_VeTRIR_b_KeepHotColdButtonStatus_Value: accessed-variable=VeTRIR_b_KeepHotColdButtonStatus.Value, variation-point={short-label=vpIN_VeTRIR_b_KeepHotColdButtonStatus_Value, sw-syscond=1}
              IN_VeTRIR_b_LoadShed_Value: accessed-variable=VeTRIR_b_LoadShed.Value, variation-point={short-label=vpIN_VeTRIR_b_LoadShed_Value, sw-syscond=1}
              IN_VeTRIR_b_SCCActv_Value: accessed-variable=VeTRIR_b_SCCActv.Value, variation-point={short-label=vpIN_VeTRIR_b_SCCActv_Value, sw-syscond=1}
              IN_VeTRIR_b_TrunkStatus_Value: accessed-variable=VeTRIR_b_TrunkStatus.Value, variation-point={short-label=vpIN_VeTRIR_b_TrunkStatus_Value, sw-syscond=1}
              IN_VeTRIR_e_HVACSt_Value: accessed-variable=VeTRIR_e_HVACSt.Value, variation-point={short-label=vpIN_VeTRIR_e_HVACSt_Value, sw-syscond=1}
              IN_VeVLDR_b_EEXV_PerfDiag_FltDtct_Value: accessed-variable=VeVLDR_b_EEXV_PerfDiag_FltDtct.Value, variation-point={short-label=vpIN_VeVLDR_b_EEXV_PerfDiag_FltDtct_Value, sw-syscond=1}
              IN_VeVLDR_b_EEXV_PressElctrFlt_FltDtct_Value: accessed-variable=VeVLDR_b_EEXV_PressElctrFlt_FltDtct.Value, variation-point={short-label=vpIN_VeVLDR_b_EEXV_PressElctrFlt_FltDtct_Value, sw-syscond=1}
              IN_VeVLDR_b_EEXV_PressSens_FltDtct_Value: accessed-variable=VeVLDR_b_EEXV_PressSens_FltDtct.Value, variation-point={short-label=vpIN_VeVLDR_b_EEXV_PressSens_FltDtct_Value, sw-syscond=1}
              IN_VeVLDR_b_EEXV_TempElctrFlt_FltDtct_Value: accessed-variable=VeVLDR_b_EEXV_TempElctrFlt_FltDtct.Value, variation-point={short-label=vpIN_VeVLDR_b_EEXV_TempElctrFlt_FltDtct_Value, sw-syscond=1}
              IN_VeVLDR_b_EXV_PerfDiag_FltDtct_Value: accessed-variable=VeVLDR_b_EXV_PerfDiag_FltDtct.Value, variation-point={short-label=vpIN_VeVLDR_b_EXV_PerfDiag_FltDtct_Value, sw-syscond=1}
              IN_VeVLDR_b_EXV_PressElctrFlt_FltDtct_Value: accessed-variable=VeVLDR_b_EXV_PressElctrFlt_FltDtct.Value, variation-point={short-label=vpIN_VeVLDR_b_EXV_PressElctrFlt_FltDtct_Value, sw-syscond=1}
              IN_VeVLDR_b_EXV_PressSens_FltDtct_Value: accessed-variable=VeVLDR_b_EXV_PressSens_FltDtct.Value, variation-point={short-label=vpIN_VeVLDR_b_EXV_PressSens_FltDtct_Value, sw-syscond=1}
              IN_VeVLDR_b_EXV_TempElctrFlt_FltDtct_Value: accessed-variable=VeVLDR_b_EXV_TempElctrFlt_FltDtct.Value, variation-point={short-label=vpIN_VeVLDR_b_EXV_TempElctrFlt_FltDtct_Value, sw-syscond=1}
              IN_VeVLDR_b_EXV_TempSens_FltDtct_Value: accessed-variable=VeVLDR_b_EXV_TempSens_FltDtct.Value, variation-point={short-label=vpIN_VeVLDR_b_EXV_TempSens_FltDtct_Value, sw-syscond=1}
              IN_VeVLDR_b_OEXV_PerfDiag_FltDtct_Value: accessed-variable=VeVLDR_b_OEXV_PerfDiag_FltDtct.Value, variation-point={short-label=vpIN_VeVLDR_b_OEXV_PerfDiag_FltDtct_Value, sw-syscond=1}
              IN_VeVLDR_b_OEXV_PressElctrFlt_FltDtct_Value: accessed-variable=VeVLDR_b_OEXV_PressElctrFlt_FltDtct.Value, variation-point={short-label=vpIN_VeVLDR_b_OEXV_PressElctrFlt_FltDtct_Value, sw-syscond=1}
              IN_VeVLDR_b_OEXV_PressSens_FltDtct_Value: accessed-variable=VeVLDR_b_OEXV_PressSens_FltDtct.Value, variation-point={short-label=vpIN_VeVLDR_b_OEXV_PressSens_FltDtct_Value, sw-syscond=1}
              IN_VeVTLR_e_DschrgSysSts_Value: accessed-variable=VeVTLR_e_DschrgSysSts.Value, variation-point={short-label=vpIN_VeVTLR_e_DschrgSysSts_Value, sw-syscond=1}
          data-send-points:
            31 x access:
              OUT_VeTPCR_t_BatPerWU_ThrmlCond_Timer_Value: accessed-variable=VeTPCR_t_BatPerWU_ThrmlCond_Timer.Value, variation-point={short-label=vpOUT_VeTPCR_t_BatPerWU_ThrmlCond_Timer_Value, sw-syscond=1}
              OUT_VeTPCR_b_PeriodWup_Msg2_Value: accessed-variable=VeTPCR_b_PeriodWup_Msg2.Value, variation-point={short-label=vpOUT_VeTPCR_b_PeriodWup_Msg2_Value, sw-syscond=1}
              OUT_VeTPCR_t_SC_PrecTimer_Value: accessed-variable=VeTPCR_t_SC_PrecTimer.Value, variation-point={short-label=vpOUT_VeTPCR_t_SC_PrecTimer_Value, sw-syscond=1}
              OUT_VeTPCR_e_SC_WakeUp_Value: accessed-variable=VeTPCR_e_SC_WakeUp.Value, variation-point={short-label=vpOUT_VeTPCR_e_SC_WakeUp_Value, sw-syscond=1}
              OUT_VeTPCR_t_TimeToDeparture_Value: accessed-variable=VeTPCR_t_TimeToDeparture.Value, variation-point={short-label=vpOUT_VeTPCR_t_TimeToDeparture_Value, sw-syscond=1}
              OUT_VeTPCR_b_CabPrecDny_BattCond_Value: accessed-variable=VeTPCR_b_CabPrecDny_BattCond.Value, variation-point={short-label=vpOUT_VeTPCR_b_CabPrecDny_BattCond_Value, sw-syscond=1}
              OUT_VeTPCR_e_CabReqSt_Msgs_Value: accessed-variable=VeTPCR_e_CabReqSt_Msgs.Value, variation-point={short-label=vpOUT_VeTPCR_e_CabReqSt_Msgs_Value, sw-syscond=1}
              OUT_VeTPCR_e_KeepHotColdSts_Value: accessed-variable=VeTPCR_e_KeepHotColdSts.Value, variation-point={short-label=vpOUT_VeTPCR_e_KeepHotColdSts_Value, sw-syscond=1}
              OUT_VeTPCR_e_KeepHotColdHMI_Value: accessed-variable=VeTPCR_e_KeepHotColdHMI.Value, variation-point={short-label=vpOUT_VeTPCR_e_KeepHotColdHMI_Value, sw-syscond=1}
              OUT_VeTPCR_b_KeyOffCabCond_Value: accessed-variable=VeTPCR_b_KeyOffCabCond.Value, variation-point={short-label=vpOUT_VeTPCR_b_KeyOffCabCond_Value, sw-syscond=1}
              OUT_VeTPCR_e_ProactiveCondStat_Value: accessed-variable=VeTPCR_e_ProactiveCondStat.Value, variation-point={short-label=vpOUT_VeTPCR_e_ProactiveCondStat_Value, sw-syscond=1}
              OUT_VeTPCR_e_ProactiveCondMode_Value: accessed-variable=VeTPCR_e_ProactiveCondMode.Value, variation-point={short-label=vpOUT_VeTPCR_e_ProactiveCondMode_Value, sw-syscond=1}
              OUT_VeTPCR_e_CabinPreCondReqStat_Value: accessed-variable=VeTPCR_e_CabinPreCondReqStat.Value, variation-point={short-label=vpOUT_VeTPCR_e_CabinPreCondReqStat_Value, sw-syscond=1}
              OUT_VeTPCR_b_ClimateFail_Value: accessed-variable=VeTPCR_b_ClimateFail.Value, variation-point={short-label=vpOUT_VeTPCR_b_ClimateFail_Value, sw-syscond=1}
              OUT_VeTPCR_e_RacePrepState_Value: accessed-variable=VeTPCR_e_RacePrepState.Value, variation-point={short-label=vpOUT_VeTPCR_e_RacePrepState_Value, sw-syscond=1}
              OUT_VeTPCR_b_RacePrepAmbCheck_Value: accessed-variable=VeTPCR_b_RacePrepAmbCheck.Value, variation-point={short-label=vpOUT_VeTPCR_b_RacePrepAmbCheck_Value, sw-syscond=1}
              OUT_VeTPCR_T_RacePrep_ModulOverTmp_Value: accessed-variable=VeTPCR_T_RacePrep_ModulOverTmp.Value, variation-point={short-label=vpOUT_VeTPCR_T_RacePrep_ModulOverTmp_Value, sw-syscond=1}
              OUT_VeTPCR_T_RacePrep_ModulUnderTmp_Value: accessed-variable=VeTPCR_T_RacePrep_ModulUnderTmp.Value, variation-point={short-label=vpOUT_VeTPCR_T_RacePrep_ModulUnderTmp_Value, sw-syscond=1}
              OUT_VeTPCR_T_RacePrep_SOCTrgt_Value: accessed-variable=VeTPCR_T_RacePrep_SOCTrgt.Value, variation-point={short-label=vpOUT_VeTPCR_T_RacePrep_SOCTrgt_Value, sw-syscond=1}
              OUT_VeTPCR_t_RacePrep_DeacTime_Value: accessed-variable=VeTPCR_t_RacePrep_DeacTime.Value, variation-point={short-label=vpOUT_VeTPCR_t_RacePrep_DeacTime_Value, sw-syscond=1}
              OUT_VeTPCR_T_RacePrep_ThrmlTrgt_Value: accessed-variable=VeTPCR_T_RacePrep_ThrmlTrgt.Value, variation-point={short-label=vpOUT_VeTPCR_T_RacePrep_ThrmlTrgt_Value, sw-syscond=1}
              OUT_VeTPCR_b_RacePrepEVSysStatus_Value: accessed-variable=VeTPCR_b_RacePrepEVSysStatus.Value, variation-point={short-label=vpOUT_VeTPCR_b_RacePrepEVSysStatus_Value, sw-syscond=1}
              OUT_VeTPCR_b_RSA_BatCrit_Msg3_Value: accessed-variable=VeTPCR_b_RSA_BatCrit_Msg3.Value, variation-point={short-label=vpOUT_VeTPCR_b_RSA_BatCrit_Msg3_Value, sw-syscond=1}
              OUT_VeTPCR_b_RdyForShtDwn_Value: accessed-variable=VeTPCR_b_RdyForShtDwn.Value, variation-point={short-label=vpOUT_VeTPCR_b_RdyForShtDwn_Value, sw-syscond=1}
              OUT_VeTPCR_e_ThrmPerWup_State_Value: accessed-variable=VeTPCR_e_ThrmPerWup_State.Value, variation-point={short-label=vpOUT_VeTPCR_e_ThrmPerWup_State_Value, sw-syscond=1}
              OUT_VeTPCR_e_PerWup_BattEngCond_State_Value: accessed-variable=VeTPCR_e_PerWup_BattEngCond_State.Value, variation-point={short-label=vpOUT_VeTPCR_e_PerWup_BattEngCond_State_Value, sw-syscond=1}
              OUT_VeTPCR_dT_PerWpCond_EngTmpErr_Value: accessed-variable=VeTPCR_dT_PerWpCond_EngTmpErr.Value, variation-point={short-label=vpOUT_VeTPCR_dT_PerWpCond_EngTmpErr_Value, sw-syscond=1}
              OUT_VeTPCR_dT_PerWpCond_BatTmpErr_Value: accessed-variable=VeTPCR_dT_PerWpCond_BatTmpErr.Value, variation-point={short-label=vpOUT_VeTPCR_dT_PerWpCond_BatTmpErr_Value, sw-syscond=1}
              OUT_VeTPCR_b_HtrOrEAC_FltRawPrst_Value: accessed-variable=VeTPCR_b_HtrOrEAC_FltRawPrst.Value, variation-point={short-label=vpOUT_VeTPCR_b_HtrOrEAC_FltRawPrst_Value, sw-syscond=1}
              OUT_VeTPCR_T_CabinTempSetPt_Value: accessed-variable=VeTPCR_T_CabinTempSetPt.Value, variation-point={short-label=vpOUT_VeTPCR_T_CabinTempSetPt_Value, sw-syscond=1}
              OUT_VeTPCR_I_RacePrepCurrentLim_Value: accessed-variable=VeTPCR_I_RacePrepCurrentLim.Value, variation-point={short-label=vpOUT_VeTPCR_I_RacePrepCurrentLim_Value, sw-syscond=1}
          parameter access CALPRM_KeTHMR_b_TurtleMd_SelDial_KeTHMR_b_TurtleMd_SelDial: accessed-parameter=KeTHMR_b_TurtleMd_SelDial.KeTHMR_b_TurtleMd_SelDial, variation-point={short-label=vpCALPRM_KeTHMR_b_TurtleMd_SelDial_KeTHMR_b_TurtleMd_SelDial, sw-syscond=1}
          parameter access CALPRM_KeTHMR_e_TurtleMd_Dial_KeTHMR_e_TurtleMd_Dial: accessed-parameter=KeTHMR_e_TurtleMd_Dial.KeTHMR_e_TurtleMd_Dial, variation-point={short-label=vpCALPRM_KeTHMR_e_TurtleMd_Dial_KeTHMR_e_TurtleMd_Dial, sw-syscond=1}
        TPCR_PwrOff
          data-send-points:
            6 x access:
              OUT_NeTPCR_b_RS_CabPrecDeny_Prev_NeTPCR_b_RS_CabPrecDeny_Prev: accessed-variable=NeTPCR_b_RS_CabPrecDeny_Prev.NeTPCR_b_RS_CabPrecDeny_Prev
              OUT_NeTPCR_b_HoldCabPrecFailLtch_NeTPCR_b_HoldCabPrecFailLtch: accessed-variable=NeTPCR_b_HoldCabPrecFailLtch.NeTPCR_b_HoldCabPrecFailLtch
              OUT_EeTPCR_e_HoldClusterMsg_EeTPCR_e_HoldClusterMsg: accessed-variable=EeTPCR_e_HoldClusterMsg.EeTPCR_e_HoldClusterMsg
              OUT_EeTPCR_e_HoldClusterMsg_KHC_EeTPCR_e_HoldClusterMsg_KHC: accessed-variable=EeTPCR_e_HoldClusterMsg_KHC.EeTPCR_e_HoldClusterMsg_KHC
              OUT_NeTPCR_Pct_WupSOC_NeTPCR_Pct_WupSOC: accessed-variable=NeTPCR_Pct_WupSOC.NeTPCR_Pct_WupSOC
              OUT_NeTPCR_b_12VloadShed_NeTPCR_b_12VloadShed: accessed-variable=NeTPCR_b_12VloadShed.NeTPCR_b_12VloadShed
      27 x variation point proxy, all with category=CONDITION:
        Variant_TPCR_1: condition-access=1
        Variant_TPCR_{10..12}: condition-access=0
        Variant_TPCR_{13..17}: condition-access=1
        Variant_TPCR_18: condition-access=0
        Variant_TPCR_19: condition-access=1
        Variant_TPCR_20: condition-access=1
        Variant_TPCR_21: condition-access=0
        Variant_TPCR_22: condition-access=0
        Variant_TPCR_{23..28}: condition-access=1
        Variant_TPCR_3: condition-access=1
        Variant_TPCR_4: condition-access=0
        Variant_TPCR_5: condition-access=0
        Variant_TPCR_6: condition-access=1
        Variant_TPCR_7: condition-access=0
        Variant_TPCR_8: condition-access=1
        Variant_TPCR_9: condition-access=1
